VERSION ""

NS_ :

BS_:

BU_: VCU BCM SS IPC ABS ACU
VAL_TABLE_ Rolling_Counter_0x85 15 "Invalid" ;
VAL_TABLE_ ACU_Crash_Sts 3 "Invalid Value" 2 "Invalid Value" 1 "Crash_Detected" 0 "No_Event" ;
VAL_TABLE_ ACU_Airbag_Deployment_Status 3 "Invalid Value" 2 "Invalid Value" 1 "Airbag_Deployment" 0 "No_Airbag_Deployment" ;
VAL_TABLE_ Rolling_Counter_0x381 15 "Invalid" ;
VAL_TABLE_ ACU_Seat_Occupancy_Passenger 3 "Failure" 2 "Not_Available" 1 "Seat Occupied" 0 "Seat_Not_Occupied" ;
VAL_TABLE_ ACU_Seat_Belt_Status_Passenger 3 "Failure" 2 "Not_Available" 1 "Buckled" 0 "Not_buckled" ;
VAL_TABLE_ ACU_Seat_Belt_Status_Driver 3 "Failure" 2 "Not_Available" 1 "Buckled" 0 "Not_buckled" ;
VAL_TABLE_ Alive_ACU_0x488 21 "Invalid" ;
VAL_TABLE_ ACU_Malfunction 0 "ACU_Failure" 1 "ACU_Normal_Operation" ;
VAL_TABLE_ ACU_Pre_Drive_Check 0 "ACU_Pre_Drive_Check" 1 "ACU_Normal_Operation" ;
VAL_TABLE_ ACU_in_Plant_Mode 0 "ACU_in_Plant_Mode" 1 "ACU_in_Normal_Mode" ;
VAL_TABLE_ ACU_PAB_Suppression 0 "Not_Suppressed" 1 "Suppressed" 2 "Function Failure" 3 "Invalid_Value" ;
VAL_TABLE_ ACU_Airbag_Disabled 0 "ACU_AirBag_Disabled" 1 "ACU_Normal_Operation" ;
VAL_TABLE_ ACU_Development_Calibration 0 "ACU_Dev_Calibrated" 1 "ACU_Normal_Operation" ;
VAL_TABLE_ ACU_In_Disposal_Mode 0 "ACU_In_Disposal_Mode" 1 "ACU_Normal_Operation" ;
VAL_TABLE_ ACU_VehicleFailureLevel 0 "Normal" 1 "Slight Fault" 2 "Minor fault" 3 "General fault" 4 "Serious Fault" 5 "Fatal fault" ;
VAL_TABLE_ ACU_Seatbelt_Reminder_Request 0 "Seatbelt reminder NOT activated" 1 "Seatbelt reminder activated" ;
VAL_TABLE_ ACU_SBR_Chime_Req 0 "No Active Chime" 1 "Active Chime" ;
VAL_TABLE_ ACU_SBR_Blinking_Req 0 "No Blinking" 1 "Blinking 1Hz" ;
VAL_TABLE_ ABS_DTCDecReqTorque 4095 " Invalid" ;
VAL_TABLE_ ABS_DTCActiveSts 0 "Not Active" 1 " Active" ;
VAL_TABLE_ ABS_DTCSystemSts 0 "No Fault" 1 "Fault" ;
VAL_TABLE_ ABS_DTCDecReqTorqueV 0 "Invalid" 1 "Valid" ;
VAL_TABLE_ ABS_ASRDecReqTorque 4095 " Invalid" ;
VAL_TABLE_ ABS_ASRSwState 0 "OFF(关闭PTC功能)" 1 "ON(开启PTC功能)" ;
VAL_TABLE_ ABS_ASRActiveSts 0 "Not Active" 1 " Active" ;
VAL_TABLE_ ABS_ASRSystemSts 0 "Normal" 1 "Fault" ;
VAL_TABLE_ ABS_ASRDecReqTorqueV 0 "Invalid" 1 "Valid" ;
VAL_TABLE_ ABS_MasterCylinderPressure 4095 "Invalid" ;
VAL_TABLE_ ALIVE_ABS_0x118 15 "Invalid" ;
VAL_TABLE_ ABS_HazardLightsOnReq 0 "No request" 1 "request" ;
VAL_TABLE_ ABS_BrakeLightsOnReq 0 "No request" 1 "request" ;
VAL_TABLE_ ABS_TcsFlgFlt 1 "Failure" 0 "no Failure" ;
VAL_TABLE_ ABS_TCS_Active 1 "active" 0 "inactive" ;
VAL_TABLE_ ABS_ABSActive 1 "active" 0 "inactive" ;
VAL_TABLE_ ABS_EBDFault 1 "Fault" 0 "Normal" ;
VAL_TABLE_ ABS_ABSFault 1 "Fault" 0 "Normal" ;
VAL_TABLE_ ABS_TCS_OFF_State 1 "open" 0 "close" ;
VAL_TABLE_ ABS_VehicleFailureLevel 0 "Normal" 1 "Slight Fault" 2 "Minor fault" 3 "General fault" 4 "Serious Fault" 5 "Fatal fault" ;
VAL_TABLE_ ABS_RBSInhibitFlag 0 "Not Inhibit" 1 "Inhibit" ;
VAL_TABLE_ ABS_EBDActive 1 "active" 0 "inactive" ;
VAL_TABLE_ ABS_VehicleSpeed 32767 "Invalid" ;
VAL_TABLE_ ABS_VehicleSpeedV 0 "Invalid" 1 "Valid" ;
VAL_TABLE_ ABS_WheelSpeedFL 8191 "Invalid" ;
VAL_TABLE_ ABS_PulseCounterFLV 0 "Invalid" 1 "Valid" ;
VAL_TABLE_ ABS_WheelSpeedFLV 0 "Invalid" 1 "Valid" ;
VAL_TABLE_ ABS_WheelSpeedFR 8191 "Invalid" ;
VAL_TABLE_ ABS_PulseCounterFRV 0 "Invalid" 1 "Valid" ;
VAL_TABLE_ ABS_WheelSpeedFRV 0 "Invalid" 1 "Valid" ;
VAL_TABLE_ ABS_WheelSpeedRL 8191 "Invalid" ;
VAL_TABLE_ ABS_PulseCounterRLV 0 "Invalid" 1 "Valid" ;
VAL_TABLE_ ABS_WheelSpeedRLV 0 "Invalid" 1 "Valid" ;
VAL_TABLE_ ABS_WheelSpeedRR 8191 "Invalid" ;
VAL_TABLE_ ABS_PulseCounterRRV 0 "Invalid" 1 "Valid" ;
VAL_TABLE_ ABS_WheelSpeedRRV 0 "Invalid" 1 "Valid" ;
VAL_TABLE_ VCU_VehicleFailureLevel 0 "Normal" 1 "Slight Fault" 2 "Minor fault" 3 "General fault" 4 "Serious Fault" 5 "Fatal fault" ;
VAL_TABLE_ VCU_EDSCAN_ERR 1 "Error" 0 "Normal" ;
VAL_TABLE_ VCU_BmsCAN_ERR 1 "Error" 0 "Normal" ;
VAL_TABLE_ VCU_DcdcCAN_ERR 1 "Error" 0 "Normal" ;
VAL_TABLE_ VCU_AbsCAN_ERR 1 "Error" 0 "Normal" ;
VAL_TABLE_ VCU_ACUCAN_ERR 1 "Error" 0 "Normal" ;
VAL_TABLE_ VCU_BcmCAN_ERR_reserved 1 "Error" 0 "Normal" ;
VAL_TABLE_ VCU_BrakeSys_Err 1 "Error" 0 "Normal" ;
VAL_TABLE_ VCU_AccPed_ERR 1 "Error" 0 "Normal" ;
VAL_TABLE_ VCU_Shift_ERR 1 "Error" 0 "Normal" ;
VAL_TABLE_ VCU_EPSCAN_ERR 1 "Error" 0 "Normal" ;
VAL_TABLE_ VCU_EvccCAN_ERR 1 "Error" 0 "Normal" ;
VAL_TABLE_ VCU_FlgHVIL_ERR 1 "Error" 0 "Normal" ;
VAL_TABLE_ VCU_ObcCAN_ERR 1 "Error" 0 "Normal" ;
VAL_TABLE_ VCU_SSCAN_ERR 1 "Error" 0 "Normal" ;
VAL_TABLE_ VCU_EacCAN_ERR 1 "Error" 0 "Normal" ;
VAL_TABLE_ VCU_AccPedalOutRange 1 "Error" 0 "Normal" ;
VAL_TABLE_ VCU_CreepDisable_stt 0 "Enable" 1 "disable" ;
VAL_TABLE_ VCU_RDCSts 0 "inactive" 1 "Active" ;
VAL_TABLE_ VCU_RBCSts 0 "inactive" 1 "Active" ;
VAL_TABLE_ VCU_BrkPedalSWSts 0 "Notpressed" 1 "pressed" 2 "notused" 3 "Invalid" ;
VAL_TABLE_ Brakefluid_levelSts 0 "Normal" 1 "Low" 2 "Disconnect" 3 "reserve" ;
VAL_TABLE_ VCU_HandBrakeSts 0 "released" 1 "notreleased" ;
VAL_TABLE_ VCU_RegenLevelfeed 0 "OFF" 1 "ON" ;
VAL_TABLE_ VCU_PowerLimit 0 "NoLimit" 1 "Limit" ;
VAL_TABLE_ VCU_AccPedaPosValid 0 "Valid" 1 "Invalid" ;
VAL_TABLE_ VCU_VehicleHVStatus 0 "NotReady" 1 "HVOn" 2 "Ready" ;
VAL_TABLE_ VCU_VacuumPresWrn 0 "Normal" 1 "Slight Insufficient" 2 "Serious Insufficient" 3 "Invalid" ;
VAL_TABLE_ VCU_VacuumSts 0 "Normal" 1 "slow leak" 2 "quick leak" 3 "Invalid" ;
VAL_TABLE_ VCU_InstantPowerConsump 1023 "Invalid" ;
VAL_TABLE_ VCU_AveragePowerConsump 1023 "Invalid" ;
VAL_TABLE_ VCU_LowSOCWarning 0 "Normal" 1 "Low SOC" ;
VAL_TABLE_ VCU_TqReductionRqstResponse 0 "inactive" 1 "Active" ;
VAL_TABLE_ VCU_DrvModeSts 0 "Normal(正常模式)" 1 "Eco(经济模式)" 2 "Sport(运动模式)" 3 "Reserved(预留)" ;
VAL_TABLE_ VCU_VacuumPumpEna 1 "Enable" 0 "Disable" ;
VAL_TABLE_ ALIVE_VCU_0x155 15 "Invalid" ;
VAL_TABLE_ VCU_VecChrgRqst 0 "Default" 1 "permit" 2 "forbid" ;
VAL_TABLE_ VCU_Vechg_Status 3 "Charging Fault" 2 "Charging Complete" 1 "Charging in process" 0 "Charging not in process" ;
VAL_TABLE_ VCU_VecOptMod 0 "Sleep(休眠)" 1 "Initial(初始化)" 2 "PowerOn(上电)" 3 "Drive(行驶)" 4 "Charging(充电)" 5 "PowerOFF(下电)" 6 "Err(故障)" 7 "LimpHome" 8 "LVCharging(馈电补电)" ;
VAL_TABLE_ VCU_BMSHvPowOnRqst 1 "allow" 0 "forbid" ;
VAL_TABLE_ VCU_VecActGearStsV 1 "Invalid" 0 "Valid" ;
VAL_TABLE_ VCU_VecActGearSts 7 "Fault" 6 "Reserved" 5 "Reserved" 4 "Reserved" 3 "D" 2 "N" 1 "R" 0 "P" ;
VAL_TABLE_ VCU_LV_topupSts 3 "Rserved" 2 "Finish supply" 1 "suppling" 0 "dissupply" ;
VAL_TABLE_ VCU_DrTorqRqstV 1 "Invalid" 0 "Valid" ;
VAL_TABLE_ VCU_ABS_TrqReqOrLmt 65535 "Invalid" ;
VAL_TABLE_ VCU_RemainMileageVD 0 "Valid" 1 "Invalid" ;
VAL_TABLE_ ALIVE_VCU_0x123 15 "Invalid" ;
VAL_TABLE_ VCU_Drive_TargetTqMin 1023 "Invalid" ;
VAL_TABLE_ VCU_Drive_TargetTqMax 1023 "Invalid" ;
VAL_TABLE_ Rolling_Counter_0x20D 15 "Invalid" ;
VAL_TABLE_ VCU_ODO 1048575 "Invalid" ;
VAL_TABLE_ Rolling_Counter_0x432 15 "Invalid" ;
VAL_TABLE_ IPC_FOTA_State 0 "INIT" 1 "NORMAL" 2 "FOTA FLASHING" 3 "Reserved" 4 "FAIL-SAFE-ERROR" 5 "Reserved" 6 "REMOTE DIAGNOSTICS" 7 "Invalid" ;
VAL_TABLE_ VCU_FOTA_StateConfirm 0 "INIT" 1 "NORMAL" 2 "FOTA FLASHING" 3 "Reserved" 4 "FAIL-SAFE-ERROR" 5 "Reserved" 6 "REMOTE DIAGNOSTICS" 7 "Invalid" ;
VAL_TABLE_ IPC_Wiper_Repair_Mode 0 "Off" 1 "On" 2 "no action" 3 "Invalid" ;
VAL_TABLE_ IPC_St_Dimming 15 "Invalid" 14 "Level 15" 13 "Level 14" 12 "Level 13" 11 "Level 12" 10 "Level 11" 9 "Level 10" 8 "Level 9" 7 "Level 8" 6 "Level 7" 5 "Level 6" 4 "Level 5" 3 "Level 4" 2 "Level 3" 1 "Level 2" 0 "Level 1" ;
VAL_TABLE_ IPC_TripA 65535 "Invalid" ;
VAL_TABLE_ IPC_AverageConsumptionTripA 1023 "Invalid" ;
VAL_TABLE_ IPC_AverageSpeedTripA 4095 "Invalid" ;
VAL_TABLE_ IPC_VehicleFailureLevel 0 "Normal" 1 "Slight Fault" 2 "Minor fault" 3 "General fault" 4 "Serious Fault" 5 "Fatal fault" ;
VAL_TABLE_ IPC_VehSpd 32767 "Invalid" ;
VAL_TABLE_ IPC_Year 255 "Invalid" ;
VAL_TABLE_ IPC_Month 15 "Invalid" ;
VAL_TABLE_ IPC_SelFCheckStatus 1 "selF-check Finish" 0 "selF-checking" ;
VAL_TABLE_ IPC_Day 31 "Invalid" ;
VAL_TABLE_ IPC_Hour 31 "Invalid" ;
VAL_TABLE_ IPC_Min 63 "Invalid" ;
VAL_TABLE_ IPC_Sec 63 "Invalid" ;
VAL_TABLE_ IPC_ODO 1048575 "Invalid" ;
VAL_TABLE_ IPC_ChargeScheduleSet 0 "Disable" 1 "Enabled" 2 "No Action" 3 "Reserved" ;
VAL_TABLE_ IPC_ChargingRequest 0 "No Effect" 1 "Request scheduled start charging" 2 "Request stop" 3 "Reserved" ;
VAL_TABLE_ IPC_EnergyRecSet 0 "OFF(关闭)" 1 "ON(开启)" 2 "Reserved(预留)" 3 "Reserved(预留)" ;
VAL_TABLE_ IPC_HSA_Set 0 "OFF" 1 "ON" 2 "Reserved" 3 "Invalid" ;
VAL_TABLE_ IPC_DriveModeSet 0 "NoReq" 1 "NormalMode" 2 "ECOmode" 3 "SportMode(预留)" ;
VAL_TABLE_ IPC_VCU_CreepDisable_Stt 0 "No request" 1 "request" ;
VAL_TABLE_ IPC_DriveLockSpeedCtl 0 "OFF" 1 "5KMH" 2 "10KMH" 3 "15KMH" 4 "20KMH" 5 "25KMH" 6 "Signal invalid" ;
VAL_TABLE_ MFS_RightControl 0 "Button not Pressed" 1 "Short Press" 2 "Long Press" 3 "Signal invalid" ;
VAL_TABLE_ MFS_LeftControl 0 "Button not Pressed" 1 "Short Press" 2 "Long Press" 3 "Signal invalid" ;
VAL_TABLE_ MFS_DownControl 0 "Button not Pressed" 1 "Short Press" 2 "Long Press" 3 "Signal invalid" ;
VAL_TABLE_ MFS_UpControl 0 "Button not Pressed" 1 "Short Press" 2 "Long Press" 3 "Signal invalid" ;
VAL_TABLE_ MFS_Failure 0 "No Error" 1 "Error" ;
VAL_TABLE_ MFS_VOL_D 3 "Signal invalid" 2 "Long Press" 1 "Short Press" 0 "Unpress" ;
VAL_TABLE_ MFS_VOL_U 3 "Signal invalid" 2 "Long Press" 1 "Short Press" 0 "Unpress" ;
VAL_TABLE_ MFS_OK_Control 0 "Button not Pressed" 1 "Short Press" 2 "Long Press" 3 "Signal invalid" ;
VAL_TABLE_ Rolling_Counter_0x108 15 "Invalid" ;
VAL_TABLE_ SS_DriveModeReq_reserved 1 "press" 0 "no press" ;
VAL_TABLE_ SS_TargetGearReq 7 "Reserved" 4 "Invalid" 3 "D" 2 "N" 1 "R" 0 "Stop Charging" ;
VAL_TABLE_ SS_Fault 6 "Received Date from BCM is invalid" 5 "Received Date from VCU is invalid" 4 "Supply voltage failure" 3 "Position sensor failure" 2 "CAN communication fail" 1 "Shifter failure" 0 "normal" ;
VAL_TABLE_ FR_Wipercontrol_switch 7 "Invalid " 6 "reserved " 5 "reserved " 4 "High " 3 "Int2 " 2 "Int1 " 1 "Low " 0 "OFF" ;
VAL_TABLE_ Front_Wash 3 "Invalid " 2 "Wash " 1 "Mist" 0 "OFF" ;
VAL_TABLE_ SS_FogLight_reserved 0 "OFF" 1 "ON" ;
VAL_TABLE_ RR_Wiper 3 "Invalid " 2 "Wash " 1 "Wipe " 0 "OFF" ;
VAL_TABLE_ SS_lane_change_lampSts 0 "OFF" 1 "Left lane change" 2 "Right lane change" 3 "Reserved" ;
VAL_TABLE_ SS_Overtaking_lamp 0 "OFF" 1 "ON" ;
VAL_TABLE_ SS_TurnIndicatorSts 0 "OFF" 1 "Left On" 2 "Right On" 3 "Reserved" ;
VAL_TABLE_ SS_PosLmpSts 0 "OFF " 1 "ON" ;
VAL_TABLE_ SS_LowBeamSts 0 "OFF" 1 "ON" ;
VAL_TABLE_ SS_HighBeamSts 0 "OFF" 1 "ON" ;
VAL_TABLE_ BCM_FrontLeftDoorAjarStatus 0 "Closed" 1 "Opened" 2 "Reserved" 3 "Signal invalid" ;
VAL_TABLE_ BCM_FrontRightDoorAjarStatus 0 "Closed" 1 "Opened" 2 "Reserved" 3 "Signal invalid" ;
VAL_TABLE_ BCM_RightDoorLockStatusDrv 0 "Unlcoked" 1 "Locked" 2 "Reserved" 3 "Signal invalid" ;
VAL_TABLE_ BCM_LeftDoorLockStatusDrv 0 "Unlcoked" 1 "Locked" 2 "Reserved" 3 "Signal invalid" ;
VAL_TABLE_ BCM_ATWS_St 0 "Secured" 1 "Unsecured" 2 "Alarm" 3 "Partly secured" 4 "Security Failure" 5 "Reserved" 6 "Reserved" 7 "Signal invalid" ;
VAL_TABLE_ BCM_STAT_DoorSpeedLock 0 "OFF" 1 "5KMH" 2 "10KMH" 3 "15KMH" 4 "20KMH" 5 "25KMH" 6 "Signal invalid" ;
VAL_TABLE_ BCM_TurnIndicatorSts 0 "OFF" 1 "LeftOn" 2 "RightOn" 3 "Hazard warning light" ;
VAL_TABLE_ BCM_PosLmpSts 0 "OFF" 1 "ON" 2 "Fault(Reserved)" 3 "SignalInvalid" ;
VAL_TABLE_ BCM_LowBeamSts 0 "OFF" 1 "ON" 2 "Fault(Reserved)" 3 "SignalInvalid" ;
VAL_TABLE_ BCM_HighBeamSts 0 "OFF" 1 "ON" 2 "Fault(Reserved)" 3 "SignalInvalid" ;
VAL_TABLE_ BCM_BrakeLightSts 0 "OFF" 1 "ON" 2 "Fault(Reserved)" 3 "SignalInvalid" ;
VAL_TABLE_ BCM_ReverseLightSts 0 "OFF" 1 "ON" 2 "Fault(Reserved)" 3 "SignalInvalid" ;
VAL_TABLE_ BCM_STAT_LightActivation 0 "OFF" 1 "PositionLight" 2 "LowBeam" 3 "AutoLight" 4 "Reserved" 5 "Reserved" 6 "Reserved" 7 "Signalinvalid" ;
VAL_TABLE_ BCM_Fr_domelampSts 0 "OFF" 1 "ON" 2 "Fault(Reserved)" 3 "SignalInvalid" ;
VAL_TABLE_ BCM_LicensePlateLightSts 0 "OFF" 1 "ON" 2 "Fault(Reserved)" 3 "SignalInvalid" ;
VAL_TABLE_ BCM_STAT_InteriorLight 0 "OFF" 1 "ON" 2 "Fault(Reserved)" 3 "SignalInvalid" ;
VAL_TABLE_ BCM_LV_topupReq 0 "inactive" 1 "Active" 2 "Rserved" 3 "Rserved" ;
VAL_TABLE_ BCM_BatteryVoltage 597 "Invalid" ;
VAL_TABLE_ BCM_Key_CheckSts 0 "Passed" 1 "Invalid" ;
VAL_TABLE_ BCM_Press_BrkPedal_Alert 0 "inactive" 1 "Active" ;
VAL_TABLE_ BCM_EmergencyStop 0 "Normal" 1 "EmergencyStop" 2 "Rserved" 3 "Invalid" ;
VAL_TABLE_ BCM_IGN1RelayOutputSts 0 "inactive" 1 "Active" 2 "Reserved" 3 "Reserved" ;
VAL_TABLE_ BCM_ACCRelayOutputSts 0 "inactive" 1 "Active" 2 "Reserved" 3 "Reserved" ;
VAL_TABLE_ BCM_FLWIN_Postion_Reserved 0 "NotActive" 1 "Closed(Top)" 2 "Open(Bottom)" 3 "80%-Close(Reserved)" 4 "Open-80%(Reserved)" 5 "opening" 6 "closing" 7 "Reserved" ;
VAL_TABLE_ BCM_KEY_MatchSts 0 "No Match" 1 "Match Success" 2 "Match Failed" 3 "Matching" ;
VAL_TABLE_ BCM_FRWIN_Postion_Reserved 0 "NotActive" 1 "Closed(Top)" 2 "Open(Bottom)" 3 "80%-Close(Reserved)" 4 "Open-80%(Reserved)" 5 "opening" 6 "closing" 7 "Reserved" ;
VAL_TABLE_ BCM_PowerMode 0 "OFF" 1 "ACC" 2 "ON" 3 "START" ;
VAL_TABLE_ BCM_BrakeSwSts 0 "Notpressed" 1 "pressed" 2 "notused" 3 "Invalid" ;
VAL_TABLE_ BCM_VehicleFailureLevel 0 "Normal" 1 "Slight Fault" 2 "Minor fault" 3 "General fault" 4 "Serious Fault" 5 "Fatal fault" ;
VAL_TABLE_ BCM_Anti_theftAlarmSetSts 0 "Light" 1 "Horn" 2 "Both" 3 "Invalid" ;
VAL_TABLE_ BCM_FMH_SetSts 0 "OFF" 1 "30s" 2 "60s" 3 "90s" ;
VAL_TABLE_ BCM_IGN1RelayFaultSts 0 "No Fault" 1 "Fault" 2 "Reserved" 3 "Signal Invalid" ;
VAL_TABLE_ BCM_ACCRelayFaultSts 0 "No Fault" 1 "Fault" 2 "Reserved" 3 "Signal Invalid" ;
VAL_TABLE_ EDS_VCU_CtrMode 0 "Inactive" 1 "Toque control mode" 2 "Anti-slide slope" 3 "reserved" ;
VAL_TABLE_ EDS_MotorSpdVD 0 "Valid" 1 "Invalid" ;
VAL_TABLE_ EDS_MotorTqVD 0 "Valid" 1 "Invalid" ;
VAL_TABLE_ EDS_MotorTq 65534 "Abnormal" 65535 "Invaild" ;
VAL_TABLE_ EDS_MotorSpd 65534 "Abnormal" 65535 "Invaild" ;
VAL_TABLE_ EDS_HSA_Sts 0 "Inactive" 1 "Active" 2 "Reserved" 3 "Invalid" ;
VAL_TABLE_ EDS_DriveSTS 0 "Regeneration control" 1 "Drive control" 2 "Zero control" ;
VAL_TABLE_ EDS_StsMode 0 "DeFault(默认值)" 1 "Init(初始化)" 2 "Standby(待机)" 3 "Precharge(预充)" 4 "Normal(正常运行)" 5 "HVReady(高压上电完成)" 11 "ShutDown(关闭)" 12 "AFterRun(运行后)" 13 "Failure" 14 "PowerOFF(下电)" ;
VAL_TABLE_ EDS_VehicleFailureLevel 0 "Normal" 1 "Slight Fault" 2 "Minor fault" 3 "General fault" 4 "Serious Fault" 5 "Fatal fault" ;
VAL_TABLE_ EDS_HSA_Fault 0 "Normal" 1 "Level 1" 2 "Level 2" 3 "Invalid" ;
VAL_TABLE_ ALIVE_EDS_0x367 15 "Invalid" ;
VAL_TABLE_ EDS_MotTempSenFault 0 "Normal" 1 "Error" ;
VAL_TABLE_ EDS_EDSOverTempAlarm 0 "Normal" 1 "Error" ;
VAL_TABLE_ EDS_EDSOverTempFault 0 "Normal" 1 "Error" ;
VAL_TABLE_ EDS_LV_VotagtFault 0 "Normal" 1 "Error" ;
VAL_TABLE_ EDS_PhashOverCurrentSWFault 0 "Normal" 1 "Error" ;
VAL_TABLE_ EDS_EDSCurrentSenVFault 0 "Normal" 1 "Error" ;
VAL_TABLE_ EDS_EDSCurrentSenWFault 0 "Normal" 1 "Error" ;
VAL_TABLE_ EDS_EDSHVOverVoltageAlarm 0 "Normal" 1 "Error" ;
VAL_TABLE_ EDS_EDSHVOverVoltageFault 0 "Normal" 1 "Error" ;
VAL_TABLE_ EDS_EDSHVUnderVoltageAlarm 0 "Normal" 1 "Error" ;
VAL_TABLE_ EDS_EDSHVUnderVoltageFault 0 "Normal" 1 "Error" ;
VAL_TABLE_ EDS_MotOverTempAlarm 0 "Normal" 1 "Error" ;
VAL_TABLE_ EDS_MotOverTempFault 0 "Normal" 1 "Error" ;
VAL_TABLE_ EDS_EDSDisChgFault 0 "Normal" 1 "Error" ;
VAL_TABLE_ EDS_EDSHVSenFault 0 "Normal" 1 "Error" ;
VAL_TABLE_ EDS_12VOverVoltageAlarm 0 "Normal" 1 "Error" ;
VAL_TABLE_ EDS_12VUnderVoltageAlarm 0 "Normal" 1 "Error" ;
VAL_TABLE_ EDS_MotOverAlarm 0 "Normal" 1 "Error" ;
VAL_TABLE_ EDS_MotOverFault 0 "Normal" 1 "Error" ;
VAL_TABLE_ EDS_PhashOverCurrentHWFault 0 "Normal" 1 "Error" ;
VAL_TABLE_ EDS_EDSCurrentSenUFault 0 "Normal" 1 "Error" ;
VAL_TABLE_ EDS_VCULostFault 0 "Normal" 1 "Error" ;
VAL_TABLE_ EDS_BMSLostFault 0 "Normal" 1 "Error" ;
VAL_TABLE_ EDS_MotRotSenFault 0 "Normal" 1 "Error" ;
VAL_TABLE_ EDS_MotBlockedFault 0 "Normal" 1 "Error" ;
VAL_TABLE_ EDS_EDSChksumFault 0 "Normal" 1 "Error" ;
VAL_TABLE_ EDS_MotTrqLimtFault 0 "Normal" 1 "Error" ;
VAL_TABLE_ EDS_VCUChksumFault 0 "Normal" 1 "Error" ;
VAL_TABLE_ EDS_EDSEnableFault 0 "Normal" 1 "Error" ;
VAL_TABLE_ EDS_IGBTFault 0 "Normal" 1 "Error" ;
VAL_TABLE_ EDS_CANBUSOFFFault 0 "Normal" 1 "Error" ;
VAL_TABLE_ EDS_EDSTempSensorErr 0 "Normal" 1 "Error" ;
VAL_TABLE_ EDS_HWCapOverVolt 0 "Normal" 1 "Error" ;
VAL_TABLE_ EDS_SWCapOverVolt 0 "Normal" 1 "Error" ;
VAL_TABLE_ EDS_EDSMemoryFlt 0 "Normal" 1 "Error" ;
VAL_TABLE_ EDS_InitMode 0 "Normal" 1 "Error" ;
VAL_TABLE_ Rolling_counter_0x17E 15 "Invalid" ;
VAL_TABLE_ EPS_S_WarningLampYellow 0 "OFF" 1 "ON" ;
VAL_TABLE_ EPS_S_SaFeLampRed 0 "OFF" 1 "ON" ;
VAL_TABLE_ EPS_SteerWheelAngle 65535 "Invalid" ;
VAL_TABLE_ EPS_SteerWhlRotSpd 16383 "Invalid" ;
VAL_TABLE_ EPS_SteerWheelRotSpdStatus 0 "Valid" 1 "Invalid" ;
VAL_TABLE_ EPS_SteeringAngleValid 0 "Valid" 1 "Invalid" ;
VAL_TABLE_ EPS_VehicleFailureLevel 0 "Normal" 1 "Slight Fault" 2 "Minor fault" 3 "General fault" 4 "Serious Fault" 5 "Fatal fault" ;
VAL_TABLE_ EPS_status 0 "NoFailure" 1 "SlightFailure" 2 "CriticalFailure" 3 "FatalFailure" ;
VAL_TABLE_ EPS_Calibrated 0 "NotCalibrated" 1 "Calibrated" ;
VAL_TABLE_ EPS_Systemstatus 0 "NoFailure" 1 "SlightFailure" 2 "CriticalFailure" 3 "FatalFailure" ;
VAL_TABLE_ Alive_SAS_0x17F 15 "Invalid" ;
VAL_TABLE_ EPS_SteeringTorque 4095 "Invalid" ;
VAL_TABLE_ EPS_SASFailure 0 "Failure" 1 "No failure" ;
VAL_TABLE_ EPS_SASStsSnsr 1 "sensor value valid" 0 "sensor value Invalid" ;
VAL_TABLE_ EPS_TorqSensorStatus 0 "Valid" 1 "Invalid" ;
VAL_TABLE_ EPS_Mode 3 " Invalid" 1 "low assist" 0 "Full assist" ;
VAL_TABLE_ EPS_EpsFailed 1 "Failed" 0 "not Failed" ;
VAL_TABLE_ Rolling_Counter_0x2A1 15 "Invalid" ;
VAL_TABLE_ EVCC_ChargeGunSts 1 "Plug In" 0 "no Plug in" ;
VAL_TABLE_ EVCC_VehicleFailureLevel 0 "Normal" 1 "Slight Fault" 2 "Minor fault" 3 "General fault" 4 "Serious Fault" 5 "Fatal fault" ;
VAL_TABLE_ EVCC_ChargeMode 2 "DC Mode " 1 "AC Mode " 0 "Default" ;
VAL_TABLE_ EVCC_CP_Sts 12 "F~" 11 "E~" 10 "D~" 9 "C~" 8 "B~" 7 "A~" 6 "F" 5 "E" 4 "D" 3 "C" 2 "B" 1 "A" 0 "No CP" ;
VAL_TABLE_ EVCC_PP_Value 7 "CC GND" 6 "1500" 5 "680" 4 "220" 3 "100" 2 "Connection" 1 "Half Connection " 0 "No Connection" ;
VAL_TABLE_ EVCC_Lock_Sts 4 "Error" 3 "Unlocking" 2 "Locked" 1 "Locking " 0 "Unlock" ;
VAL_TABLE_ EVCC_DCFCPortsTempErr 1 "Error" 0 "Normal" ;
VAL_TABLE_ Rolling_Counter_0x3E0 15 "Invalid" ;
VAL_TABLE_ EVCC_IPC_Ack_ChgSche_stt 0 "Disabled" 1 "Enabled" 2 "Reserved" 3 "Invalid" ;
VAL_TABLE_ Rolling_Counter_0x219 15 "Invalid" ;
VAL_TABLE_ EVCC_ChargeAllow 1 "Allow " 0 "Not allow" ;
VAL_TABLE_ Rolling_Counter_0x125 15 "Invalid" ;
VAL_TABLE_ Rolling_Counter_0x216 15 "Invalid" ;
VAL_TABLE_ BMS_RemainChargeTime 16383 "Invalid" ;
VAL_TABLE_ BMS_ChgVoltage_REQ 16383 "Invalid" ;
VAL_TABLE_ BMS_ChgCurrent_REQ 65535 "Invalid" ;
VAL_TABLE_ Rolling_Counter_0x215 15 "Invalid" ;
VAL_TABLE_ BMS_SOE 255 "Invalid" ;
VAL_TABLE_ BMS_HWCrash_Sts 1 "Crash " 0 "No Crash" ;
VAL_TABLE_ BMS_HVIL_STS 2 "out of range" 1 "Open" 0 "Closed" ;
VAL_TABLE_ BMS_IGN_Sts 1 "ON " 0 "OFF" ;
VAL_TABLE_ BMS_Sys_STS 8 "Invalid" 7 "Failure, unable to operate" 6 "BCU Sleep mode" 5 "Successful Power Down" 4 "Power Down process" 3 "Successful Power Down of HV" 2 "Successful High Voltage Power Up" 1 "Self-check passes, can be high-voltage" 0 "Initialization of power on, self-checking" ;
VAL_TABLE_ BMS_HVOnOff_STS 3 "Fail to HV on " 2 "HV On " 1 "Precharge " 0 "HV Off" ;
VAL_TABLE_ BMS_Balance_STS 1 "active " 0 "Inactive" ;
VAL_TABLE_ BMS_BatBalance_ERR 1 "normal " 0 "Error" ;
VAL_TABLE_ BMS_ISU_Status 3 "Level3(<100 Ohms/V)" 2 "Level2(<200 Ohms/V)" 1 "Level1 <500 Ohms/V ~ >200 Ohms/V" 0 "Normal (> 500 Ohms/V)" ;
VAL_TABLE_ BMS_ERR_LEV 7 "Battery locked -Reserved" 6 "Fault, needs Shutdown and Wakeup" 5 "Emergency off condition" 4 "Delayed power down with FTTI" 3 "Power down without FTTI" 2 "Limp Home" 1 " Warning (any warning in system)" 0 "No error" ;
VAL_TABLE_ BMS_Vehicle_ERR_LEV 0 "Normal" 1 "Slight Fault" 2 "Minor fault" 3 "General fault" 4 "Serious Fault" 5 "Fatal fault" ;
VAL_TABLE_ BMS_HV_Sts 4 "AC Charging" 3 "DC Charging" 2 "HV ON" 1 "Precharge" 0 "HV Off" ;
VAL_TABLE_ BMS_Warning_Flag_Reserved_08 1 "Warning" 0 "No warning" ;
VAL_TABLE_ BMS_Warning_Flag_Reserved_07 1 "Warning" 0 "No warning" ;
VAL_TABLE_ BMS_Warning_Flag_Reserved_11 1 "Warning" 0 "No warning" ;
VAL_TABLE_ BMS_Warning_Flag_Reserved_10 1 "Warning" 0 "No warning" ;
VAL_TABLE_ BMS_Warning_Flag_Reserved_09 1 "Warning" 0 "No warning" ;
VAL_TABLE_ BMS_Warning_Flag_Reserved_13 1 "Warning" 0 "No warning" ;
VAL_TABLE_ BMS_Warning_Flag_Reserved_12 1 "Warning" 0 "No warning" ;
VAL_TABLE_ BMS_Warning_Flag_Reserved_06 1 "Warning" 0 "No warning" ;
VAL_TABLE_ BMS_Warning_Flag_Reserved_05 1 "Warning" 0 "No warning" ;
VAL_TABLE_ BMS_Warning_Flag_Reserved_04 1 "Warning" 0 "No warning" ;
VAL_TABLE_ BMS_MalfunctionSts 1 "Malfunction indicator lamp ON" 0 "Malfunction indicator lamp OFF" ;
VAL_TABLE_ BMS_LowBattery 2 "Extremely low level" 1 "Low level" 0 "No warning" ;
VAL_TABLE_ BMS_BatteryReplacement 1 "Warning" 0 "No warning" ;
VAL_TABLE_ BMS_PackTempSts 2 "Under Temperature Warning" 1 "Over Temperature Warning" 0 "No warning" ;
VAL_TABLE_ BMS_ThermalRunaway 1 "Warning" 0 "No warning" ;
VAL_TABLE_ Rolling_Counter_0x493 15 "Invalid" ;
VAL_TABLE_ Rolling_Counter_0x174 15 "Invalid" ;
VAL_TABLE_ BMS_PackCur_MEAS 65535 "Invalid" ;
VAL_TABLE_ BMS_AllowDischgCurr 65535 "Invalid" ;
VAL_TABLE_ BMS_AllowDischgCurrPeak 65535 "Invalid" ;
VAL_TABLE_ Rolling_Counter_0x176 15 "Invalid" ;
VAL_TABLE_ BMS_HVLinkVol_MEAS 65535 "Invalid" ;
VAL_TABLE_ BMS_HVPackVol_MEAS 65535 "Invalid" ;
VAL_TABLE_ Rolling_Counter_0x20B 15 "Invalid" ;
VAL_TABLE_ POD_DCDC_Max_Current_Out 1023 "Invalid" ;
VAL_TABLE_ DCDC_Temp_mosfet 255 "Invalid" ;
VAL_TABLE_ DCDC_Voltage_Output 1023 "Invalid" ;
VAL_TABLE_ DCDC_Current_Output 255 "Invalid" ;
VAL_TABLE_ DCDC_Output_STS 0 "DCDC_OFF" 1 "DCDC_STANDBY" 2 "DCDC_ON" 3 "DCDC_RESERVED" 4 "DCDC_DEGRAEDED" 5 "DCDC_FAULT_SHUTDOWN" 6 "DCDC_EMEGENCY_SHUTDOWN" 7 "DCDC_SNA" ;
VAL_TABLE_ DCDC_Temp_heatsink 255 "Invalid" ;
VAL_TABLE_ Rolling_Counter_0x406 15 "Invalid" ;
VAL_TABLE_ DCDC_FaultLevel 5 "Level5,Fatal fault" 4 "Level4,Serious fault" 3 "Level3,General fault" 2 "Level2,Minor fault" 1 "Level1,slight fault" 0 "No Fault" ;
VAL_TABLE_ DCFC_FaultLevel 0 "No Fault" 2 "Level2: Serous Fault " 3 "Level3: Fatal Fault" ;
VAL_TABLE_ Rolling_Counter_0x20A 15 "Invalid" ;
VAL_TABLE_ DCFC_Voltage_Input 1023 "Invalid" ;
VAL_TABLE_ DCDC_PTC_Temp 255 "Invalid" ;
VAL_TABLE_ DCFC_Neg_Temp_BusBar 255 "Invalid" ;
VAL_TABLE_ DCFC_STATE 0 "DCFC_Contactors_Open_e" 1 "DCFC_Contactors_Closing" 2 "DCFC_Contactors_Close" 3 "DCFC_Contactors_Opening" 4 "DCFC_Contactors_Weld" 7 "DCFC_SNA" ;
VAL_TABLE_ DCFC_PTC_Status 3 "invalid" 2 "reserved" 1 "ON" 0 "OFF" ;
VAL_TABLE_ Rolling_Counter_0x209 15 "Invalid" ;
VAL_TABLE_ BMS_MaxDischgPwr_ALW 4095 "Invalid" ;
VAL_TABLE_ BMS_MaxChgPwr_ALW 4095 "Invalid" ;
VAL_TABLE_ BMS_MaxDischgPwr_Peak 4095 "Invalid" ;
VAL_TABLE_ BMS_MaxChgPwr_Peak 4095 "Invalid" ;
VAL_TABLE_ Rolling_Counter_0x332 15 "Invalid" ;
VAL_TABLE_ BMS_PackTemp_Infor 255 "Invalid" ;
VAL_TABLE_ Rolling_Counter_0x330 15 "Invalid" ;
VAL_TABLE_ BMS_ContactorAging 2 "Fault: counter reach 98%" 1 "Warning: counter reach 90%" 0 "Normal" ;
VAL_TABLE_ Rolling_Counter_0x177 15 "Invalid" ;
VAL_TABLE_ BMS_HVBusVol_MEAS 65535 "Invalid" ;
VAL_TABLE_ BMS_HVFuseVol_MEAS 65535 "Invalid" ;
VAL_TABLE_ Rolling_Counter_0x214 15 "Invalid" ;
VAL_TABLE_ BMS_Display_SOC 1023 "Invalid" ;
VAL_TABLE_ Rolling_Counter_0x375 15 "Invalid" ;
VAL_TABLE_ BMS_MainPosRelay_ERR 1 "normal " 0 "Error" ;
VAL_TABLE_ BMS_MainPosRelay_STS 4 "stuck open" 3 "stuck closed" 2 "closed" 1 "open" 0 "reserved" ;
VAL_TABLE_ BMS_PreChgRelay_ERR 1 "normal " 0 "error" ;
VAL_TABLE_ BMS_PreChgRelay_STS 4 "stuck open" 3 "stuck closed" 2 "closed" 1 "open" 0 "reserved" ;
VAL_TABLE_ BMS_TotalNegRelay_STS 4 "stuck open" 3 "stuck closed" 2 "closed" 1 "open" 0 "reserved" ;
VAL_TABLE_ BMS_TotalNegRelay_ERR 1 "normal " 0 "Error" ;
VAL_TABLE_ Rolling_Counter_0x305 15 "Invalid" ;
VAL_TABLE_ BMS_VCU_Insulation_Mon_Sts 1 "OFF" 0 "ON" ;
VAL_TABLE_ Rolling_Counter_0x455 15 "Invalid" ;
VAL_TABLE_ BMS_PackInsu_ERR 2 "Lv2-Short to vbat and open line" 1 "Lv1 - Short to ground" 0 "Lv0-No Err" ;
VAL_TABLE_ BMS_CellVoltDiff_ERR 3 "Level3 Reserve" 2 "Level2 Serious alarm value" 1 "Level1 General alarm value" 0 "Level0 Normal" ;
VAL_TABLE_ BMS_PackOverCurr_ERR 2 "Serious Alarm value" 1 "General Alarm Value" 0 "Normal" ;
VAL_TABLE_ BMS_HVIL_Err 3 "Level3" 2 "Level2" 1 "Level1" 0 "Normal" ;
VAL_TABLE_ BMS_CellHighVol_ERR 3 "Level3 Reserve" 2 "Level2 Serious alarm value" 1 "Level1 General alarm value" 0 "Level0 Normal" ;
VAL_TABLE_ BMS_CellLowVol_ERR 3 "Level3 Reserve" 2 "Level2 Serious alarm value" 1 "Level1 General alarm value" 0 "Level0 Normal" ;
VAL_TABLE_ BMS_PackLowVol_ERR 3 "Level3 Reserve" 2 "Level2 Serious alarm value" 1 "Level1 General alarm value" 0 "Level0 Normal" ;
VAL_TABLE_ BMS_PackHighVol_ERR 3 "Level3 Reserve" 2 "Level2 Serious alarm value" 1 "Level1 General alarm value" 0 "Level0 Normal" ;
VAL_TABLE_ BMS_ProbeHighTemp_ERR 3 "Level3 Reserve" 2 "Level2 Serious alarm value" 1 "Level1 General alarm value" 0 "Level0 Normal" ;
VAL_TABLE_ BMS_ProbeTempDiff_ERR 3 "Level3 Reserve" 2 "Level2 Serious alarm value" 1 "Level1 General alarm value" 0 "Level0 Normal" ;
VAL_TABLE_ BMS_FuseStatus_ERR 1 "Fuse blow" 0 "Normal" ;
VAL_TABLE_ BMS_ProbeLowTemp_ERR 3 "Level3 Reserve" 2 "Level2 Serious alarm value" 1 "Level1 General alarm value" 0 "Level0 Normal" ;
VAL_TABLE_ Rolling_Counter_0x286 15 "Invalid" ;
VAL_TABLE_ DCFC_OUT_DC_V 65535 "Invalid" ;
VAL_TABLE_ DCFC_OUT_DC_I 16383 "Invalid" ;
VAL_TABLE_ DCFC_DCCharge_line_V 65535 "Invalid" ;
VAL_TABLE_ DCDC_evt_BUS_OFF 1 "Error" 0 "Normal" ;
VAL_TABLE_ DCDC_evt_MIA 1 "Error" 0 "Normal" ;
VAL_TABLE_ DCDC_evt_E2E 1 "Error" 0 "Normal" ;
VAL_TABLE_ DCDC_evt_Calibration_Flt 1 "Error" 0 "Normal" ;
VAL_TABLE_ DCDC_evt_flash_Failure 1 "Error" 0 "Normal" ;
VAL_TABLE_ DCDC_evt_FaultLatchCircuit 1 "Error" 0 "Normal" ;
VAL_TABLE_ DCDC_evt_HV_VoltSensFlt 1 "Error" 0 "Normal" ;
VAL_TABLE_ DCDC_evt_HV_OverVoltFlt 1 "Error" 0 "Normal" ;
VAL_TABLE_ DCDC_evt_HV_UnderVoltFlt 1 "Error" 0 "Normal" ;
VAL_TABLE_ DCDC_evt_LV_VoltSensFlt 1 "Error" 0 "Normal" ;
VAL_TABLE_ DCDC_evt_LVBatt_OverVoltFlt 1 "Error" 0 "Normal" ;
VAL_TABLE_ DCDC_evt_LVBatt_UnderVoltFlt 1 "Error" 0 "Normal" ;
VAL_TABLE_ DCDC_evt_LVBatt_SensorFlt 1 "Error" 0 "Normal" ;
VAL_TABLE_ DCDC_evt_LV_RedundancyFlt 1 "Error" 0 "Normal" ;
VAL_TABLE_ DCDC_evt_LV_CurrSensFlt 1 "Error" 0 "Normal" ;
VAL_TABLE_ DCDC_evt_LV_OverCurr 1 "Error" 0 "Normal" ;
VAL_TABLE_ DCDC_evt_ReverseCurrFlt 1 "Error" 0 "Normal" ;
VAL_TABLE_ DCDC_evt_Heater_TempSensorFlt 1 "Error" 0 "Normal" ;
VAL_TABLE_ DCDC_evt_Mosfet_TempSensorFlt 1 "Error" 0 "Normal" ;
VAL_TABLE_ DCDC_evt_Mosfet_OverTemp 1 "Error" 0 "Normal" ;
VAL_TABLE_ DCDC_evt_HeatSink_TempSensorFlt 1 "Error" 0 "Normal" ;
VAL_TABLE_ DCDC_evt_HeatSink_OverTemp 1 "Error" 0 "Normal" ;
VAL_TABLE_ DCDC_evt_Heater_OverTempFlt 1 "Error" 0 "Normal" ;
VAL_TABLE_ DCDC_evt_Heater_ShortIGBTFlt 1 "Error" 0 "Normal" ;
VAL_TABLE_ DCDC_evt_LV_ShortOutputFlt 1 "Error" 0 "Normal" ;
VAL_TABLE_ DCDC_evt_sw_BMS_CrashFlt 1 "Error" 0 "Normal" ;
VAL_TABLE_ DCDC_evt_BMS_HVILFlt 1 "Error" 0 "Normal" ;
VAL_TABLE_ DCFC_evt_BusbarSensFlt 1 "Error" 0 "Normal" ;
VAL_TABLE_ DCFC_evt_Contactor_Welded 1 "Error" 0 "Normal" ;
VAL_TABLE_ DCFC_evt_ContactorStuckOpen 1 "Error" 0 "Normal" ;
VAL_TABLE_ DCFC_evt_CP_UnderVoltFlt 1 "Error" 0 "Normal" ;
VAL_TABLE_ DCFC_evt_DataInvalidVCUFlt 1 "Error" 0 "Normal" ;
VAL_TABLE_ DCFC_evt_ChargePortSensFlt 1 "Error" 0 "Normal" ;
VAL_TABLE_ DCFC_evt_OverChargePortFlt 1 "Error" 0 "Normal" ;
VAL_TABLE_ DCFC_evt_OverBusbarTemp 1 "Error" 0 "Normal" ;
VAL_TABLE_ DCFC_evt_E2E_Flt 1 "Error" 0 "Normal" ;
VAL_TABLE_ DCFC_evt_MIA_Flt 1 "Error" 0 "Normal" ;

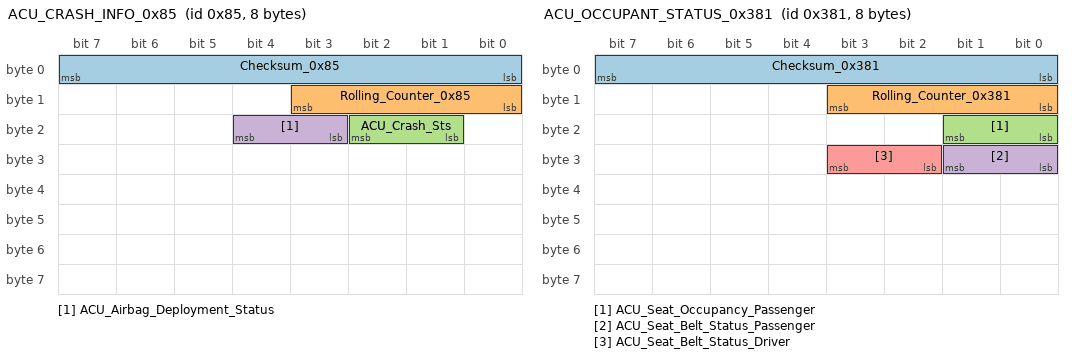
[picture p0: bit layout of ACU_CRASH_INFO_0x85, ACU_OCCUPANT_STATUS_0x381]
BO_ 133 ACU_CRASH_INFO_0x85: 8 ACU
 SG_ Checksum_0x85 : 7|8@0+ (1,0) [0|255] ""  VCU,BCM,IPC
 SG_ Rolling_Counter_0x85 : 11|4@0+ (1,0) [0|15] ""  VCU,BCM,IPC
 SG_ ACU_Crash_Sts : 18|2@0+ (1,0) [0|3] ""  VCU,BCM,IPC
 SG_ ACU_Airbag_Deployment_Status : 20|2@0+ (1,0) [0|3] ""  VCU,IPC

BO_ 897 ACU_OCCUPANT_STATUS_0x381: 8 ACU
 SG_ Checksum_0x381 : 7|8@0+ (1,0) [0|255] ""  VCU,IPC,ABS
 SG_ Rolling_Counter_0x381 : 11|4@0+ (1,0) [0|15] ""  VCU,IPC,ABS
 SG_ ACU_Seat_Occupancy_Passenger : 17|2@0+ (1,0) [0|3] ""  VCU,IPC
 SG_ ACU_Seat_Belt_Status_Passenger : 25|2@0+ (1,0) [0|3] ""  VCU,IPC
 SG_ ACU_Seat_Belt_Status_Driver : 27|2@0+ (1,0) [0|3] ""  VCU,IPC,ABS

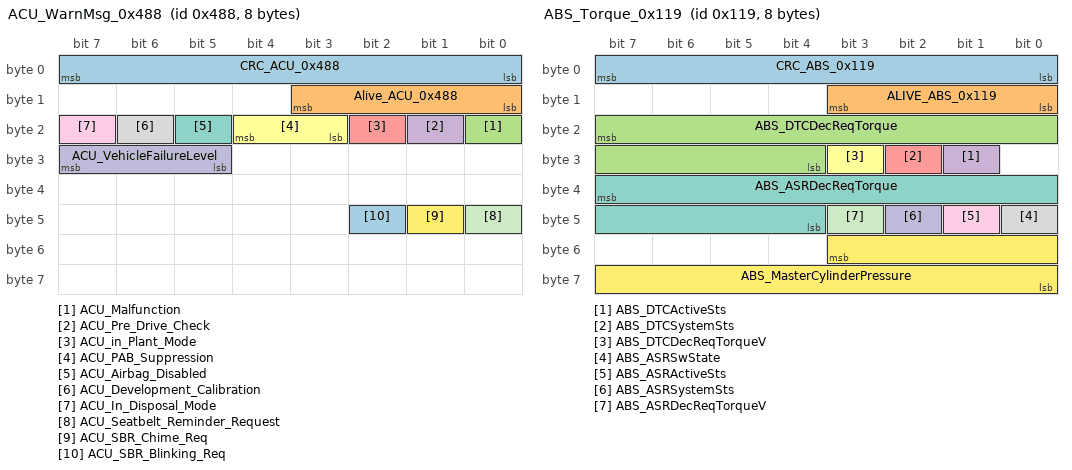
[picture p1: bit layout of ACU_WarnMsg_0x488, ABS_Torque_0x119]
BO_ 1160 ACU_WarnMsg_0x488: 8 ACU
 SG_ CRC_ACU_0x488 : 7|8@0+ (1,0) [0|255] ""  VCU,IPC
 SG_ Alive_ACU_0x488 : 11|4@0+ (1,0) [0|15] ""  VCU,IPC
 SG_ ACU_Malfunction : 16|1@0+ (1,0) [0|1] ""  VCU,IPC
 SG_ ACU_Pre_Drive_Check : 17|1@0+ (1,0) [0|1] ""  VCU,IPC
 SG_ ACU_in_Plant_Mode : 18|1@0+ (1,0) [0|1] ""  VCU,IPC
 SG_ ACU_PAB_Suppression : 20|2@0+ (1,0) [0|3] ""  VCU,IPC
 SG_ ACU_Airbag_Disabled : 21|1@0+ (1,0) [0|1] ""  VCU,IPC
 SG_ ACU_Development_Calibration : 22|1@0+ (1,0) [0|1] ""  VCU,IPC
 SG_ ACU_In_Disposal_Mode : 23|1@0+ (1,0) [0|1] ""  VCU,IPC
 SG_ ACU_VehicleFailureLevel : 31|3@0+ (1,0) [0|7] ""  VCU,IPC
 SG_ ACU_Seatbelt_Reminder_Request : 40|1@0+ (1,0) [0|1] ""  VCU,IPC
 SG_ ACU_SBR_Chime_Req : 41|1@0+ (1,0) [0|1] ""  VCU,IPC
 SG_ ACU_SBR_Blinking_Req : 42|1@0+ (1,0) [0|1] ""  VCU,IPC

BO_ 281 ABS_Torque_0x119: 8 ABS
 SG_ CRC_ABS_0x119 : 7|8@0+ (1,0) [0|255] ""  VCU
 SG_ ALIVE_ABS_0x119 : 11|4@0+ (1,0) [0|15] ""  VCU
 SG_ ABS_DTCDecReqTorque : 23|12@0+ (0.1,-200) [-200|0] "Nm"  VCU
 SG_ ABS_DTCActiveSts : 25|1@0+ (1,0) [0|1] ""  VCU
 SG_ ABS_DTCSystemSts : 26|1@0+ (1,0) [0|1] ""  VCU
 SG_ ABS_DTCDecReqTorqueV : 27|1@0+ (1,0) [0|1] ""  VCU
 SG_ ABS_ASRDecReqTorque : 39|12@0+ (0.1,0) [0|400] "Nm"  VCU
 SG_ ABS_ASRSwState : 40|1@0+ (1,0) [0|1] ""  VCU
 SG_ ABS_ASRActiveSts : 41|1@0+ (1,0) [0|1] ""  VCU
 SG_ ABS_ASRSystemSts : 42|1@0+ (1,0) [0|1] ""  VCU
 SG_ ABS_ASRDecReqTorqueV : 43|1@0+ (1,0) [0|1] ""  VCU
 SG_ ABS_MasterCylinderPressure : 51|12@0+ (1,0) [0|4094] "bar"  VCU

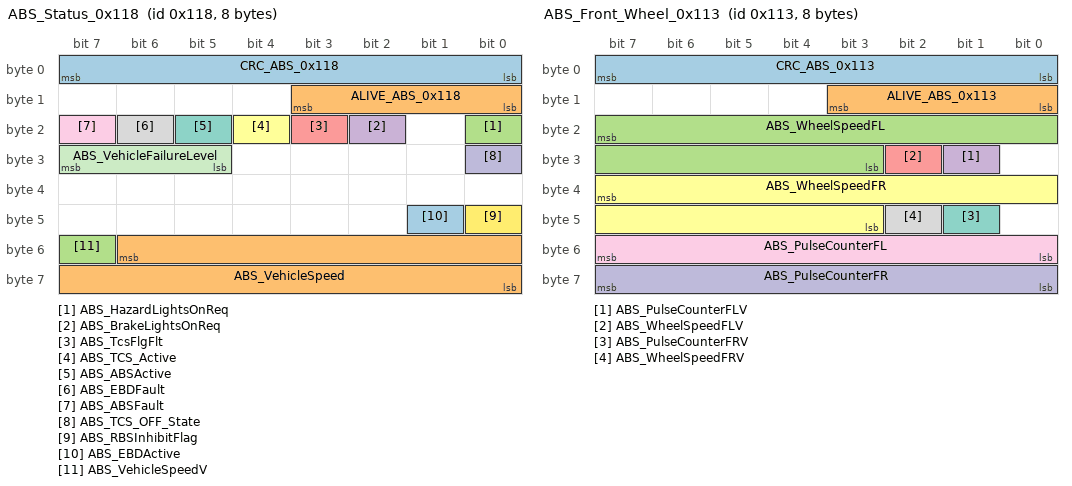
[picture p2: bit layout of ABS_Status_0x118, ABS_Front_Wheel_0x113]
BO_ 280 ABS_Status_0x118: 8 ABS
 SG_ CRC_ABS_0x118 : 7|8@0+ (1,0) [0|255] ""  VCU,BCM,SS,IPC,ACU
 SG_ ALIVE_ABS_0x118 : 11|4@0+ (1,0) [0|15] ""  VCU,BCM,SS,IPC,ACU
 SG_ ABS_HazardLightsOnReq : 16|1@0+ (1,0) [0|1] ""  VCU,BCM,SS,IPC,ACU
 SG_ ABS_BrakeLightsOnReq : 18|1@0+ (1,0) [0|1] ""  VCU,BCM,SS,IPC,ACU
 SG_ ABS_TcsFlgFlt : 19|1@0+ (1,0) [0|1] ""  VCU,BCM,SS,IPC,ACU
 SG_ ABS_TCS_Active : 20|1@0+ (1,0) [0|1] ""  VCU,BCM,SS,IPC,ACU
 SG_ ABS_ABSActive : 21|1@0+ (1,0) [0|1] ""  VCU,BCM,SS,IPC,ACU
 SG_ ABS_EBDFault : 22|1@0+ (1,0) [0|1] ""  VCU,BCM,SS,IPC,ACU
 SG_ ABS_ABSFault : 23|1@0+ (1,0) [0|1] ""  VCU,BCM,SS,IPC,ACU
 SG_ ABS_TCS_OFF_State : 24|1@0+ (1,0) [0|1] ""  VCU,BCM,SS,IPC,ACU
 SG_ ABS_VehicleFailureLevel : 31|3@0+ (1,0) [0|7] ""  VCU,BCM,SS,IPC,ACU
 SG_ ABS_RBSInhibitFlag : 40|1@0+ (1,0) [0|1] ""  VCU,BCM,SS,IPC,ACU
 SG_ ABS_EBDActive : 41|1@0+ (1,0) [0|1] ""  VCU,BCM,SS,IPC,ACU
 SG_ ABS_VehicleSpeed : 54|15@0+ (0.015625,0) [0|360] "km/h"  VCU,BCM,SS,IPC,ACU
 SG_ ABS_VehicleSpeedV : 55|1@0+ (1,0) [0|1] ""  VCU,BCM,SS,IPC,ACU

BO_ 275 ABS_Front_Wheel_0x113: 8 ABS
 SG_ CRC_ABS_0x113 : 7|8@0+ (1,0) [0|255] ""  VCU
 SG_ ALIVE_ABS_0x113 : 11|4@0+ (1,0) [0|15] ""  VCU
 SG_ ABS_WheelSpeedFL : 23|13@0+ (0.05625,0) [0|270] "km/h"  VCU
 SG_ ABS_PulseCounterFLV : 25|1@0+ (1,0) [0|1] ""  VCU
 SG_ ABS_WheelSpeedFLV : 26|1@0+ (1,0) [0|1] ""  VCU
 SG_ ABS_WheelSpeedFR : 39|13@0+ (0.05625,0) [0|270] "km/h"  VCU
 SG_ ABS_PulseCounterFRV : 41|1@0+ (1,0) [0|1] ""  VCU
 SG_ ABS_WheelSpeedFRV : 42|1@0+ (1,0) [0|1] ""  VCU
 SG_ ABS_PulseCounterFL : 55|8@0+ (1,0) [0|255] ""  VCU
 SG_ ABS_PulseCounterFR : 63|8@0+ (1,0) [0|255] ""  VCU

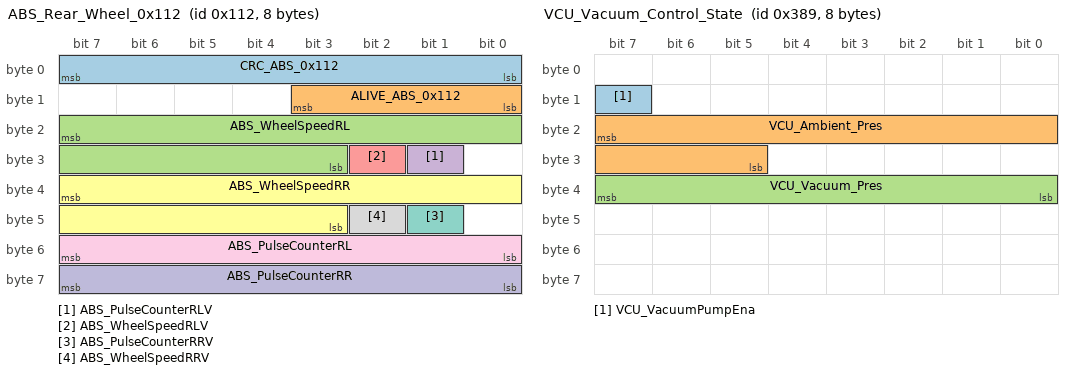
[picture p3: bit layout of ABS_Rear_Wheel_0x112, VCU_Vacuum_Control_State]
BO_ 274 ABS_Rear_Wheel_0x112: 8 ABS
 SG_ CRC_ABS_0x112 : 7|8@0+ (1,0) [0|255] ""  VCU
 SG_ ALIVE_ABS_0x112 : 11|4@0+ (1,0) [0|15] ""  VCU
 SG_ ABS_WheelSpeedRL : 23|13@0+ (0.05625,0) [0|270] "km/h"  VCU
 SG_ ABS_PulseCounterRLV : 25|1@0+ (1,0) [0|1] ""  VCU
 SG_ ABS_WheelSpeedRLV : 26|1@0+ (1,0) [0|1] ""  VCU
 SG_ ABS_WheelSpeedRR : 39|13@0+ (0.05625,0) [0|270] "km/h"  VCU
 SG_ ABS_PulseCounterRRV : 41|1@0+ (1,0) [0|1] ""  VCU
 SG_ ABS_WheelSpeedRRV : 42|1@0+ (1,0) [0|1] ""  VCU
 SG_ ABS_PulseCounterRL : 55|8@0+ (1,0) [0|255] ""  VCU
 SG_ ABS_PulseCounterRR : 63|8@0+ (1,0) [0|255] ""  VCU

BO_ 1145 VCU_Error_0x479: 8 VCU
 SG_ VCU_FaultCode : 7|8@0+ (1,0) [0|255] ""  IPC
 SG_ VCU_VehicleFailureLevel : 10|3@0+ (1,0) [0|7] ""  IPC
 SG_ VCU_EDSCAN_ERR : 16|1@0+ (1,0) [0|1] ""  IPC
 SG_ VCU_BmsCAN_ERR : 17|1@0+ (1,0) [0|1] ""  IPC
 SG_ VCU_DcdcCAN_ERR : 18|1@0+ (1,0) [0|1] ""  IPC
 SG_ VCU_AbsCAN_ERR : 19|1@0+ (1,0) [0|1] ""  IPC
 SG_ VCU_ACUCAN_ERR : 20|1@0+ (1,0) [0|1] ""  IPC
 SG_ VCU_BcmCAN_ERR_reserved : 21|1@0+ (1,0) [0|1] ""  IPC
 SG_ VCU_BrakeSys_Err : 22|1@0+ (1,0) [0|1] ""  IPC
 SG_ VCU_AccPed_ERR : 23|1@0+ (1,0) [0|1] ""  IPC
 SG_ VCU_Shift_ERR : 24|1@0+ (1,0) [0|1] ""  IPC
 SG_ VCU_EPSCAN_ERR : 25|1@0+ (1,0) [0|1] ""  IPC
 SG_ VCU_EvccCAN_ERR : 26|1@0+ (1,0) [0|1] ""  IPC
 SG_ VCU_FlgHVIL_ERR : 27|1@0+ (1,0) [0|1] ""  IPC
 SG_ VCU_ObcCAN_ERR : 41|1@0+ (1,0) [0|1] ""  IPC
 SG_ VCU_SSCAN_ERR : 39|1@0+ (1,0) [0|1] ""  IPC
 SG_ VCU_EacCAN_ERR : 38|1@0+ (1,0) [0|1] ""  IPC
 SG_ VCU_AccPedalOutRange : 40|1@0+ (1,0) [0|1] ""  IPC

BO_ 1221 VCU_Status: 8 VCU
 SG_ CRC_VCU_0x4C5 : 7|8@0+ (1,0) [0|255] ""  BCM,IPC,ABS,ACU
 SG_ ALIVE_VCU_0x4C5 : 11|4@0+ (1,0) [0|15] ""  BCM,IPC,ABS,ACU
 SG_ VCU_CreepDisable_stt : 13|1@0+ (1,0) [0|1] ""  BCM,IPC,ABS,ACU
 SG_ VCU_RDCSts : 14|1@0+ (1,0) [0|1] ""  BCM,IPC,ABS,ACU
 SG_ VCU_RBCSts : 15|1@0+ (1,0) [0|1] ""  BCM,IPC,ABS,ACU
 SG_ VCU_BrkPedalSWSts : 17|2@0+ (1,0) [0|3] ""  BCM,IPC,ABS,ACU
 SG_ Brakefluid_levelSts : 19|2@0+ (1,0) [0|3] ""  BCM,IPC,ABS,ACU
 SG_ VCU_HandBrakeSts : 20|1@0+ (1,0) [0|1] ""  BCM,IPC,ABS,ACU
 SG_ VCU_RegenLevelfeed : 21|1@0+ (1,0) [0|1] ""  BCM,IPC,ABS,ACU
 SG_ VCU_PowerLimit : 22|1@0+ (1,0) [0|1] ""  BCM,IPC,ABS,ACU
 SG_ VCU_AccPedaPosValid : 23|1@0+ (1,0) [0|1] ""  BCM,IPC,ABS,ACU
 SG_ VCU_AccPedaPos : 31|8@0+ (1,0) [0|100] "%"  BCM,IPC,ABS,ACU
 SG_ VCU_VehicleHVStatus : 33|2@0+ (1,0) [0|3] ""  BCM,IPC,ABS,ACU
 SG_ VCU_VacuumPresWrn : 35|2@0+ (1,0) [0|3] ""  BCM,IPC,ABS,ACU
 SG_ VCU_VacuumSts : 37|2@0+ (1,0) [0|3] ""  BCM,IPC,ABS,ACU
 SG_ VCU_InstantPowerConsump : 47|10@0+ (0.1,0) [0|100] "kwh/100km"  BCM,IPC,ABS,ACU
 SG_ VCU_AveragePowerConsump : 53|10@0+ (0.1,0) [0|100] "kwh/100km"  BCM,IPC,ABS,ACU
 SG_ VCU_LowSOCWarning : 56|1@0+ (1,0) [0|1] ""  BCM,IPC,ABS,ACU
 SG_ VCU_TqReductionRqstResponse : 57|1@0+ (1,0) [0|1] ""  BCM,IPC,ABS,ACU
 SG_ VCU_DrvModeSts : 59|2@0+ (1,0) [0|3] ""  BCM,IPC,ABS,ACU

BO_ 905 VCU_Vacuum_Control_State: 8 VCU
 SG_ VCU_VacuumPumpEna : 15|1@0+ (1,0) [0|1] ""  IPC
 SG_ VCU_Ambient_Pres : 23|11@0+ (0.1,0) [0|150] "kPa"  IPC
 SG_ VCU_Vacuum_Pres : 39|8@0+ (1,-150) [-150|50] "kPa"  IPC

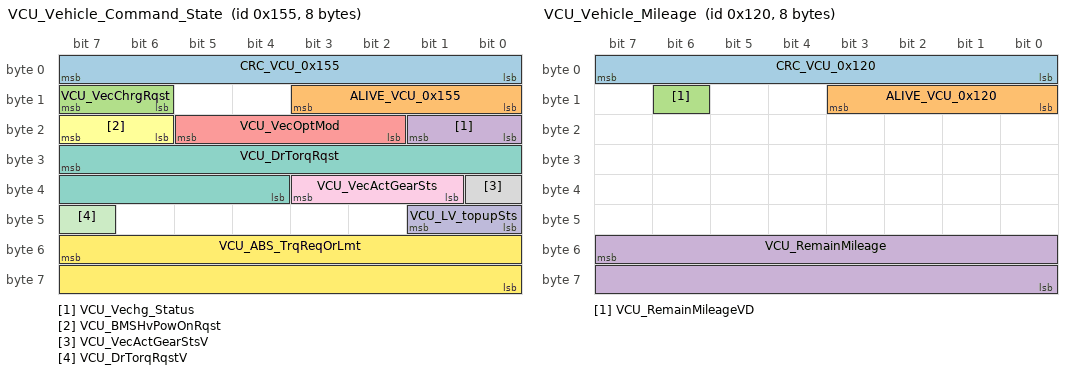
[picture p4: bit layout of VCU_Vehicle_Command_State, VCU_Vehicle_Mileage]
BO_ 341 VCU_Vehicle_Command_State: 8 VCU
 SG_ CRC_VCU_0x155 : 7|8@0+ (1,0) [0|255] ""  BCM,IPC,ABS,ACU
 SG_ ALIVE_VCU_0x155 : 11|4@0+ (1,0) [0|15] ""  BCM,IPC,ABS,ACU
 SG_ VCU_VecChrgRqst : 15|2@0+ (1,0) [0|3] ""  BCM,IPC,ABS,ACU
 SG_ VCU_Vechg_Status : 17|2@0+ (1,0) [0|3] ""  BCM,IPC,ABS,ACU
 SG_ VCU_VecOptMod : 21|4@0+ (1,0) [0|15] ""  BCM,IPC,ABS,ACU
 SG_ VCU_BMSHvPowOnRqst : 23|2@0+ (1,0) [0|3] ""  BCM,IPC,ABS,ACU
 SG_ VCU_DrTorqRqst : 31|12@0+ (0.25,-511) [-511|511] "Nm"  BCM,IPC,ABS,ACU
 SG_ VCU_VecActGearStsV : 32|1@0+ (1,0) [0|1] ""  BCM,IPC,ABS,ACU
 SG_ VCU_VecActGearSts : 35|3@0+ (1,0) [0|7] ""  BCM,IPC,ABS,ACU
 SG_ VCU_LV_topupSts : 41|2@0+ (1,0) [0|3] ""  BCM,IPC,ABS,ACU
 SG_ VCU_DrTorqRqstV : 47|1@0+ (1,0) [0|1] ""  BCM,IPC,ABS,ACU
 SG_ VCU_ABS_TrqReqOrLmt : 55|16@0+ (0.1,-2000) [-2000|2000] "Nm"  BCM,IPC,ABS,ACU

BO_ 288 VCU_Vehicle_Mileage: 8 VCU
 SG_ CRC_VCU_0x120 : 7|8@0+ (1,0) [0|255] ""  IPC
 SG_ ALIVE_VCU_0x120 : 11|4@0+ (1,0) [0|15] ""  IPC
 SG_ VCU_RemainMileageVD : 14|1@0+ (1,0) [0|1] ""  IPC
 SG_ VCU_RemainMileage : 55|16@0+ (0.1,0) [0|1000] ""  IPC

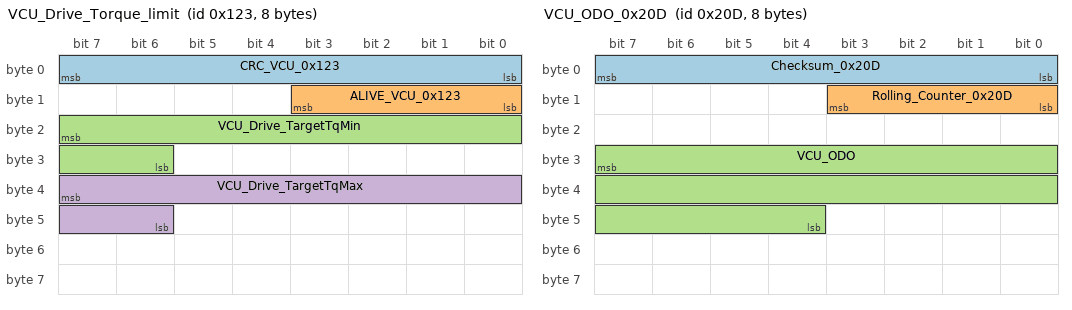
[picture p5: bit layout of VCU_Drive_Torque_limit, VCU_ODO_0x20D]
BO_ 291 VCU_Drive_Torque_limit: 8 VCU
 SG_ CRC_VCU_0x123 : 7|8@0+ (1,0) [0|255] ""  ABS
 SG_ ALIVE_VCU_0x123 : 11|4@0+ (1,0) [0|15] ""  ABS
 SG_ VCU_Drive_TargetTqMin : 23|10@0+ (1,-500) [-500|0] "Nm"  ABS
 SG_ VCU_Drive_TargetTqMax : 39|10@0+ (1,0) [0|500] "Nm"  ABS

BO_ 525 VCU_ODO_0x20D: 8 VCU
 SG_ Checksum_0x20D : 7|8@0+ (1,0) [0|255] ""  IPC
 SG_ Rolling_Counter_0x20D : 11|4@0+ (1,0) [0|15] ""  IPC
 SG_ VCU_ODO : 31|20@0+ (1,0) [0|999999] "km"  IPC

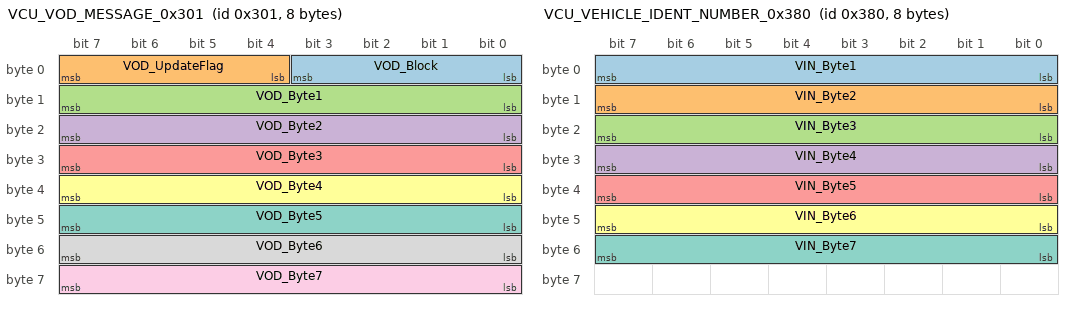
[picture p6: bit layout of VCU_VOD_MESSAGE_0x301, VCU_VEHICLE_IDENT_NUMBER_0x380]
BO_ 769 VCU_VOD_MESSAGE_0x301: 8 VCU
 SG_ VOD_Block : 3|4@0+ (1,0) [0|7] ""  IPC
 SG_ VOD_UpdateFlag : 7|4@0+ (1,0) [0|7] ""  IPC
 SG_ VOD_Byte1 : 15|8@0+ (1,0) [0|255] ""  IPC
 SG_ VOD_Byte2 : 23|8@0+ (1,0) [0|255] ""  IPC
 SG_ VOD_Byte3 : 31|8@0+ (1,0) [0|255] ""  IPC
 SG_ VOD_Byte4 : 39|8@0+ (1,0) [0|255] ""  IPC
 SG_ VOD_Byte5 : 47|8@0+ (1,0) [0|255] ""  IPC
 SG_ VOD_Byte6 : 55|8@0+ (1,0) [0|255] ""  IPC
 SG_ VOD_Byte7 : 63|8@0+ (1,0) [0|255] ""  IPC

BO_ 896 VCU_VEHICLE_IDENT_NUMBER_0x380: 8 VCU
 SG_ VIN_Byte1 : 7|8@0+ (1,0) [0|255] ""  IPC
 SG_ VIN_Byte2 : 15|8@0+ (1,0) [0|255] ""  IPC
 SG_ VIN_Byte3 : 23|8@0+ (1,0) [0|255] ""  IPC
 SG_ VIN_Byte4 : 31|8@0+ (1,0) [0|255] ""  IPC
 SG_ VIN_Byte5 : 39|8@0+ (1,0) [0|255] ""  IPC
 SG_ VIN_Byte6 : 47|8@0+ (1,0) [0|255] ""  IPC
 SG_ VIN_Byte7 : 55|8@0+ (1,0) [0|255] ""  IPC

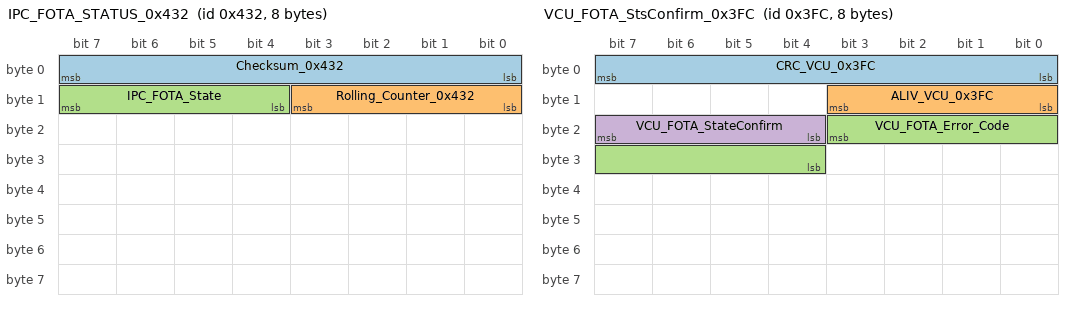
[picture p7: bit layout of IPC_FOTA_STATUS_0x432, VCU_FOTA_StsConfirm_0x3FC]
BO_ 1074 IPC_FOTA_STATUS_0x432: 8 IPC
 SG_ Checksum_0x432 : 7|8@0+ (1,0) [0|255] ""  VCU,BCM,SS,ABS,ACU
 SG_ Rolling_Counter_0x432 : 11|4@0+ (1,0) [0|15] ""  VCU,BCM,SS,ABS,ACU
 SG_ IPC_FOTA_State : 15|4@0+ (1,0) [0|14] ""  VCU,BCM,SS,ABS,ACU

BO_ 1020 VCU_FOTA_StsConfirm_0x3FC: 8 VCU
 SG_ CRC_VCU_0x3FC : 7|8@0+ (1,0) [0|255] ""  IPC
 SG_ ALIV_VCU_0x3FC : 11|4@0+ (1,0) [0|15] ""  IPC
 SG_ VCU_FOTA_Error_Code : 19|8@0+ (1,0) [0|255] ""  IPC
 SG_ VCU_FOTA_StateConfirm : 23|4@0+ (1,0) [0|14] ""  IPC

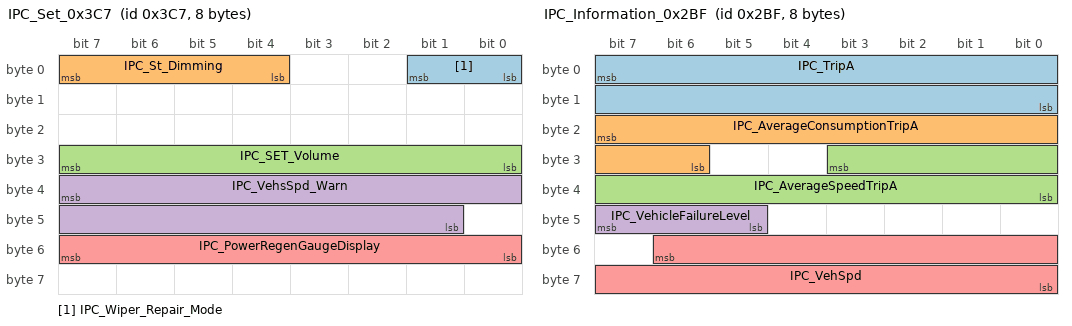
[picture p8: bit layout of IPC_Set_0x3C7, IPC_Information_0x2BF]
BO_ 967 IPC_Set_0x3C7: 8 IPC
 SG_ IPC_Wiper_Repair_Mode : 1|2@0+ (1,0) [0|3] ""  BCM,SS
 SG_ IPC_St_Dimming : 7|4@0+ (1,0) [0|15] ""  BCM,SS
 SG_ IPC_SET_Volume : 31|8@0+ (1,0) [0|32] ""  BCM
 SG_ IPC_VehsSpd_Warn : 39|15@0+ (0.01,0) [0|120] ""  BCM,SS
 SG_ IPC_PowerRegenGaugeDisplay : 55|8@0+ (1,-100) [-100|100] "%" Vector__XXX

BO_ 703 IPC_Information_0x2BF: 8 IPC
 SG_ IPC_TripA : 7|16@0+ (0.1,0) [0|999.9] "km"  VCU,BCM,ACU
 SG_ IPC_AverageConsumptionTripA : 23|10@0+ (0.1,0) [0|100] "kwh/100km"  VCU,BCM,ACU
 SG_ IPC_AverageSpeedTripA : 27|12@0+ (0.0625,0) [0|250] "km/h"  VCU,BCM,ACU
 SG_ IPC_VehicleFailureLevel : 47|3@0+ (1,0) [0|7] ""  VCU,BCM,ACU
 SG_ IPC_VehSpd : 54|15@0+ (0.01,0) [0|327.66] "kph"  VCU,BCM,ACU

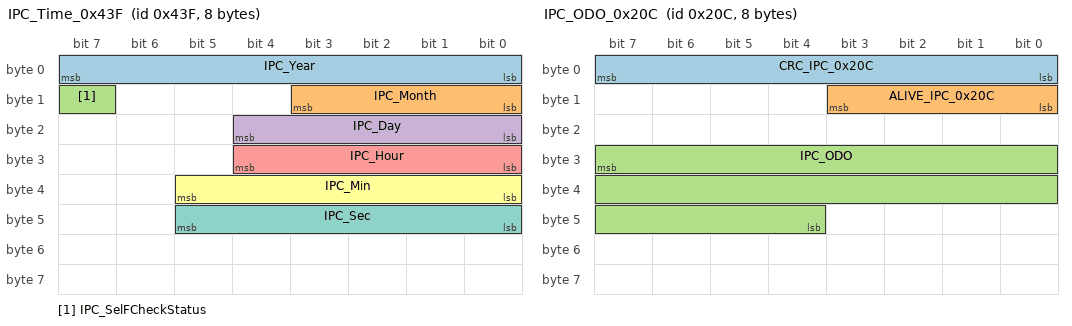
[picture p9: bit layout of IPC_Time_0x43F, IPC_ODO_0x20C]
BO_ 1087 IPC_Time_0x43F: 8 IPC
 SG_ IPC_Year : 7|8@0+ (1,2000) [2000|2255] ""  VCU,BCM,ABS,ACU
 SG_ IPC_Month : 11|4@0+ (1,0) [1|12] ""  VCU,BCM,ABS,ACU
 SG_ IPC_SelFCheckStatus : 15|1@0+ (1,0) [0|1] ""  VCU,BCM,ABS,ACU
 SG_ IPC_Day : 20|5@0+ (1,0) [1|31] ""  VCU,BCM,ABS,ACU
 SG_ IPC_Hour : 28|5@0+ (1,0) [0|31] "hour"  VCU,BCM,ABS,ACU
 SG_ IPC_Min : 37|6@0+ (1,0) [0|63] "min"  VCU,BCM,ABS,ACU
 SG_ IPC_Sec : 45|6@0+ (1,0) [0|63] "second"  VCU,BCM,ABS,ACU

BO_ 524 IPC_ODO_0x20C: 8 IPC
 SG_ CRC_IPC_0x20C : 7|8@0+ (1,0) [0|255] ""  VCU,BCM,ACU
 SG_ ALIVE_IPC_0x20C : 11|4@0+ (1,0) [0|15] ""  VCU,BCM,ACU
 SG_ IPC_ODO : 31|20@0+ (1,0) [0|999999] "km"  VCU,BCM,ACU

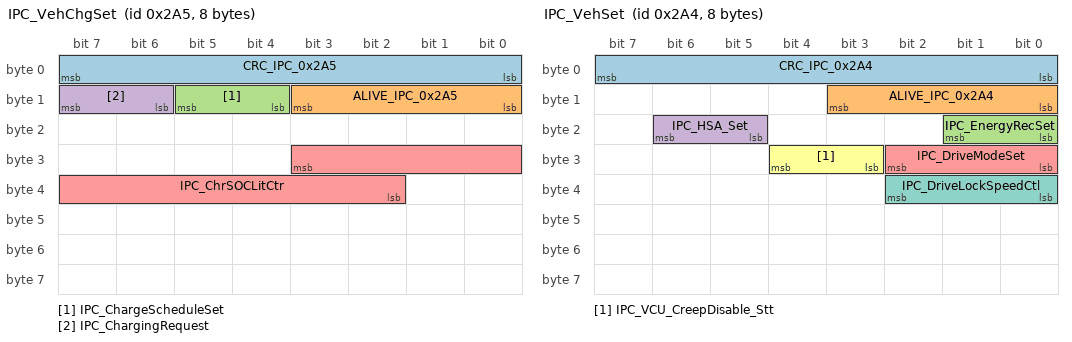
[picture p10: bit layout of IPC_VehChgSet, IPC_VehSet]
BO_ 677 IPC_VehChgSet: 8 IPC
 SG_ CRC_IPC_0x2A5 : 7|8@0+ (1,0) [0|255] ""  VCU
 SG_ ALIVE_IPC_0x2A5 : 11|4@0+ (1,0) [0|15] ""  VCU
 SG_ IPC_ChargeScheduleSet : 13|2@0+ (1,0) [0|3] ""  VCU
 SG_ IPC_ChargingRequest : 15|2@0+ (1,0) [0|3] ""  VCU
 SG_ IPC_ChrSOCLitCtr : 27|10@0+ (0.1,0) [0|1000] "%"  VCU

BO_ 676 IPC_VehSet: 8 IPC
 SG_ CRC_IPC_0x2A4 : 7|8@0+ (1,0) [0|255] ""  VCU,BCM
 SG_ ALIVE_IPC_0x2A4 : 11|4@0+ (1,0) [0|15] ""  VCU,BCM
 SG_ IPC_EnergyRecSet : 17|2@0+ (1,0) [0|3] ""  VCU,BCM
 SG_ IPC_HSA_Set : 22|2@0+ (1,0) [0|3] ""  VCU
 SG_ IPC_DriveModeSet : 26|3@0+ (1,0) [0|7] ""  VCU,BCM
 SG_ IPC_VCU_CreepDisable_Stt : 28|2@0+ (1,0) [0|3] ""  VCU,BCM
 SG_ IPC_DriveLockSpeedCtl : 34|3@0+ (1,0) [0|7] ""  VCU,BCM

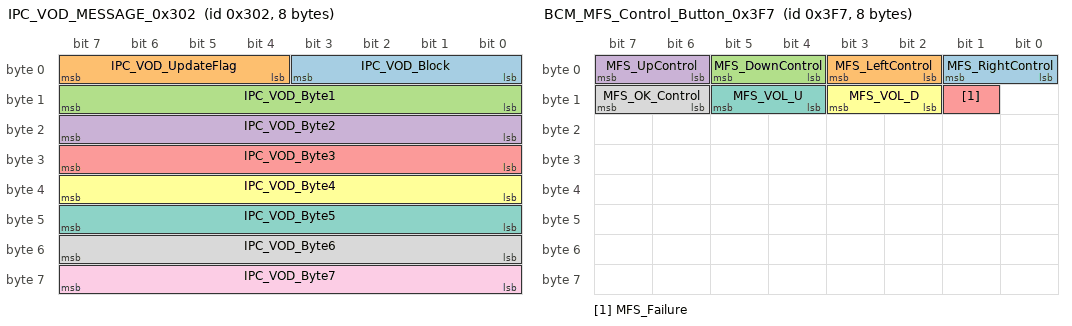
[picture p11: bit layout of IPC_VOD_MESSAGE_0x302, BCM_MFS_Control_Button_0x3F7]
BO_ 770 IPC_VOD_MESSAGE_0x302: 8 IPC
 SG_ IPC_VOD_Block : 3|4@0+ (1,0) [0|7] ""  VCU
 SG_ IPC_VOD_UpdateFlag : 7|4@0+ (1,0) [0|7] ""  VCU
 SG_ IPC_VOD_Byte1 : 15|8@0+ (1,0) [0|255] ""  VCU
 SG_ IPC_VOD_Byte2 : 23|8@0+ (1,0) [0|255] ""  VCU
 SG_ IPC_VOD_Byte3 : 31|8@0+ (1,0) [0|255] ""  VCU
 SG_ IPC_VOD_Byte4 : 39|8@0+ (1,0) [0|255] ""  VCU
 SG_ IPC_VOD_Byte5 : 47|8@0+ (1,0) [0|255] ""  VCU
 SG_ IPC_VOD_Byte6 : 55|8@0+ (1,0) [0|255] ""  VCU
 SG_ IPC_VOD_Byte7 : 63|8@0+ (1,0) [0|255] ""  VCU

BO_ 1015 BCM_MFS_Control_Button_0x3F7: 8 BCM
 SG_ MFS_RightControl : 1|2@0+ (1,0) [0|3] ""  IPC
 SG_ MFS_LeftControl : 3|2@0+ (1,0) [0|3] ""  IPC
 SG_ MFS_DownControl : 5|2@0+ (1,0) [0|3] ""  IPC
 SG_ MFS_UpControl : 7|2@0+ (1,0) [0|3] ""  IPC
 SG_ MFS_Failure : 9|1@0+ (1,0) [0|1] ""  IPC
 SG_ MFS_VOL_D : 11|2@0+ (1,0) [0|3] ""  IPC
 SG_ MFS_VOL_U : 13|2@0+ (1,0) [0|3] ""  IPC
 SG_ MFS_OK_Control : 15|2@0+ (1,0) [0|3] ""  IPC

BO_ 264 SS_DriveReq_0x108: 8 SS
 SG_ Checksum_0x108 : 7|8@0+ (1,0) [0|255] ""  VCU,BCM,IPC
 SG_ Rolling_Counter_0x108 : 11|4@0+ (1,0) [0|15] ""  VCU,BCM,IPC
 SG_ SS_DriveModeReq_reserved : 16|1@0+ (1,0) [0|1] ""  VCU,BCM,IPC
 SG_ SS_TargetGearReq : 23|3@0+ (1,0) [0|7] ""  VCU,BCM,IPC
 SG_ SS_Fault : 27|4@0+ (1,0) [0|15] ""  VCU,BCM,IPC
 SG_ FR_Wipercontrol_switch : 34|3@0+ (1,0) [0|7] ""  VCU,BCM,IPC
 SG_ Front_Wash : 36|2@0+ (1,0) [0|3] ""  VCU,BCM,IPC
 SG_ SS_FogLight_reserved : 37|1@0+ (1,0) [0|1] ""  VCU,BCM,IPC
 SG_ RR_Wiper : 39|2@0+ (1,0) [0|3] ""  VCU,BCM,IPC
 SG_ SS_lane_change_lampSts : 41|2@0+ (1,0) [0|3] ""  VCU,BCM,IPC
 SG_ SS_Overtaking_lamp : 42|1@0+ (1,0) [0|1] ""  VCU,BCM,IPC
 SG_ SS_TurnIndicatorSts : 44|2@0+ (1,0) [0|3] ""  VCU,BCM,IPC
 SG_ SS_PosLmpSts : 45|1@0+ (1,0) [0|1] ""  VCU,BCM,IPC
 SG_ SS_LowBeamSts : 46|1@0+ (1,0) [0|1] ""  VCU,BCM,IPC
 SG_ SS_HighBeamSts : 47|1@0+ (1,0) [0|1] ""  VCU,BCM,IPC
 SG_ SS_HardNumLow : 51|4@0+ (1,0) [0|15] ""  VCU,BCM,IPC
 SG_ SS_HardNumHigh : 55|4@0+ (1,0) [0|15] ""  VCU,BCM,IPC
 SG_ SS_SoftNumLow : 59|4@0+ (1,0) [0|15] ""  VCU,BCM,IPC
 SG_ SS_SoftNumHigh : 63|4@0+ (1,0) [0|15] ""  VCU,BCM,IPC

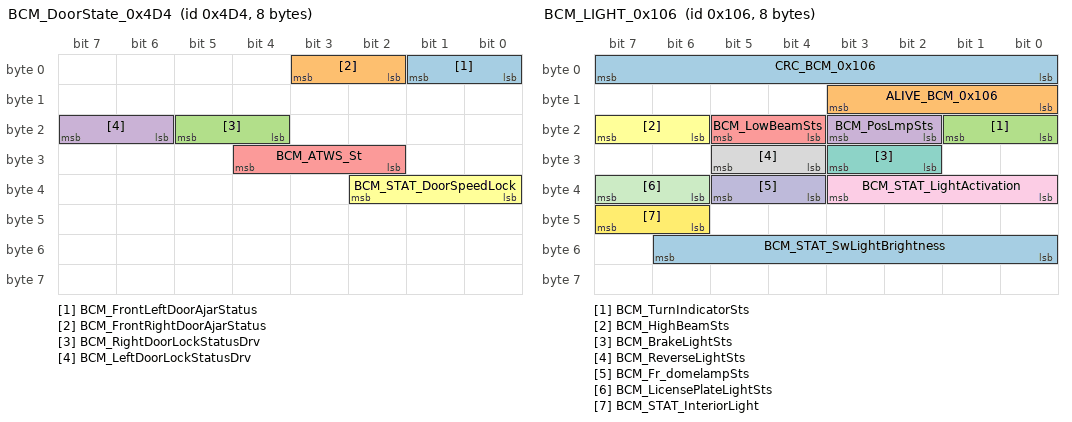
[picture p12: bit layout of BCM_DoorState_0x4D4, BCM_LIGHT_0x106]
BO_ 1236 BCM_DoorState_0x4D4: 8 BCM
 SG_ BCM_FrontLeftDoorAjarStatus : 1|2@0+ (1,0) [0|1] ""  VCU,IPC
 SG_ BCM_FrontRightDoorAjarStatus : 3|2@0+ (1,0) [0|1] ""  VCU,IPC
 SG_ BCM_RightDoorLockStatusDrv : 21|2@0+ (1,0) [0|3] ""  VCU,IPC
 SG_ BCM_LeftDoorLockStatusDrv : 23|2@0+ (1,0) [0|3] ""  VCU,IPC
 SG_ BCM_ATWS_St : 28|3@0+ (1,0) [0|7] ""  VCU,IPC
 SG_ BCM_STAT_DoorSpeedLock : 34|3@0+ (1,0) [0|7] ""  VCU,IPC

BO_ 262 BCM_LIGHT_0x106: 8 BCM
 SG_ CRC_BCM_0x106 : 7|8@0+ (1,0) [0|255] ""  VCU,IPC,ACU
 SG_ ALIVE_BCM_0x106 : 11|4@0+ (1,0) [0|15] ""  VCU,IPC,ACU
 SG_ BCM_TurnIndicatorSts : 17|2@0+ (1,0) [0|3] ""  VCU,IPC,ACU
 SG_ BCM_PosLmpSts : 19|2@0+ (1,0) [0|3] ""  VCU,IPC,ACU
 SG_ BCM_LowBeamSts : 21|2@0+ (1,0) [0|3] ""  VCU,IPC,ACU
 SG_ BCM_HighBeamSts : 23|2@0+ (1,0) [0|3] ""  VCU,IPC,ACU
 SG_ BCM_BrakeLightSts : 27|2@0+ (1,0) [0|3] ""  VCU,IPC,ACU
 SG_ BCM_ReverseLightSts : 29|2@0+ (1,0) [0|3] ""  VCU,IPC,ACU
 SG_ BCM_STAT_LightActivation : 35|4@0+ (1,0) [0|7] ""  VCU,IPC,ACU
 SG_ BCM_Fr_domelampSts : 37|2@0+ (1,0) [0|3] ""  VCU,IPC,ACU
 SG_ BCM_LicensePlateLightSts : 39|2@0+ (1,0) [0|3] ""  VCU,IPC,ACU
 SG_ BCM_STAT_InteriorLight : 47|2@0+ (1,0) [0|3] ""  VCU,IPC,ACU
 SG_ BCM_STAT_SwLightBrightness : 54|7@0+ (1,0) [0|100] "%"  VCU,IPC,ACU

BO_ 513 BCM_Status_0x201: 8 BCM
 SG_ CRC_BCM_0x201 : 7|8@0+ (1,0) [0|255] ""  VCU,SS,IPC,ABS,ACU
 SG_ ALIVE_BCM_0x201 : 11|4@0+ (1,0) [0|15] ""  VCU,SS,IPC,ABS,ACU
 SG_ BCM_LV_topupReq : 15|4@0+ (1,0) [0|3] ""  VCU,SS,IPC,ABS,ACU
 SG_ BCM_BatteryVoltage : 23|8@0+ (0.1,0) [0|25.4] "V"  VCU,SS,IPC,ABS,ACU
 SG_ BCM_Key_CheckSts : 24|1@0+ (1,0) [0|1] ""  VCU,SS,IPC,ABS,ACU
 SG_ BCM_Press_BrkPedal_Alert : 25|1@0+ (1,0) [0|1] ""  VCU,SS,IPC,ABS,ACU
 SG_ BCM_EmergencyStop : 27|2@0+ (1,0) [0|3] ""  VCU,SS,IPC,ABS,ACU
 SG_ BCM_IGN1RelayOutputSts : 29|2@0+ (1,0) [0|3] ""  VCU,SS,IPC,ABS,ACU
 SG_ BCM_ACCRelayOutputSts : 31|2@0+ (1,0) [0|3] ""  VCU,SS,IPC,ABS,ACU
 SG_ BCM_FLWIN_Postion_Reserved : 34|3@0+ (1,0) [0|7] ""  VCU,SS,IPC,ABS,ACU
 SG_ BCM_KEY_MatchSts : 36|2@0+ (1,0) [0|3] ""  VCU,SS,IPC,ABS,ACU
 SG_ BCM_FRWIN_Postion_Reserved : 39|3@0+ (1,0) [0|7] ""  VCU,SS,IPC,ABS,ACU
 SG_ BCM_BCMFaultCode : 47|8@0+ (1,0) [0|255] ""  VCU,SS,IPC,ABS,ACU
 SG_ BCM_PowerMode : 49|2@0+ (1,0) [0|3] ""  VCU,SS,IPC,ABS,ACU
 SG_ BCM_BrakeSwSts : 51|2@0+ (1,0) [0|3] ""  VCU,SS,IPC,ABS,ACU
 SG_ BCM_VehicleFailureLevel : 55|3@0+ (1,0) [0|7] ""  VCU,SS,IPC,ABS,ACU
 SG_ BCM_Anti_theftAlarmSetSts : 57|2@0+ (1,0) [0|3] ""  VCU,SS,IPC,ABS,ACU
 SG_ BCM_FMH_SetSts : 59|2@0+ (1,0) [0|3] ""  VCU,SS,IPC,ABS,ACU
 SG_ BCM_IGN1RelayFaultSts : 61|2@0+ (1,0) [0|3] ""  VCU,SS,IPC,ABS,ACU
 SG_ BCM_ACCRelayFaultSts : 63|2@0+ (1,0) [0|3] ""  VCU,SS,IPC,ABS,ACU

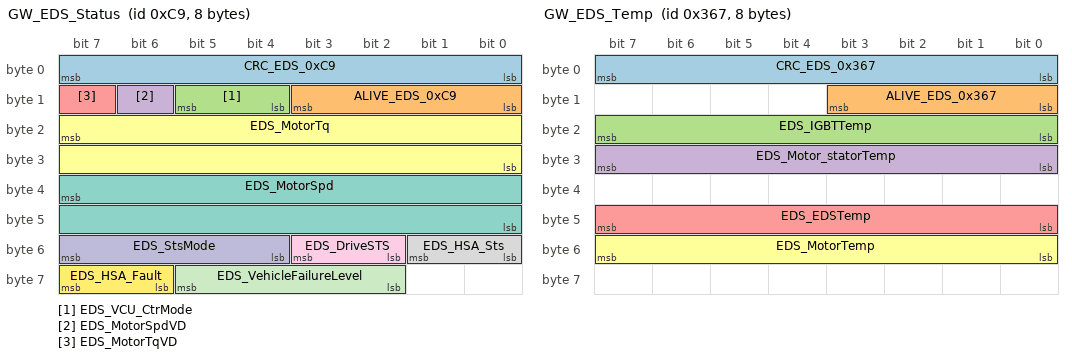
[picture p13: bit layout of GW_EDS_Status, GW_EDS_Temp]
BO_ 201 GW_EDS_Status: 8 VCU
 SG_ CRC_EDS_0xC9 : 7|8@0+ (1,0) [0|255] ""  IPC,ABS,ACU
 SG_ ALIVE_EDS_0xC9 : 11|4@0+ (1,0) [0|15] ""  IPC,ABS,ACU
 SG_ EDS_VCU_CtrMode : 13|2@0+ (1,0) [0|3] ""  IPC,ABS,ACU
 SG_ EDS_MotorSpdVD : 14|1@0+ (1,0) [0|1] ""  IPC,ABS,ACU
 SG_ EDS_MotorTqVD : 15|1@0+ (1,0) [0|1] ""  IPC,ABS,ACU
 SG_ EDS_MotorTq : 23|16@0+ (0.1,-1200) [-1200|1200] "Nm"  IPC,ABS,ACU
 SG_ EDS_MotorSpd : 39|16@0+ (1,-20000) [-20000|45531] "rpm"  IPC,ABS,ACU
 SG_ EDS_HSA_Sts : 49|2@0+ (1,0) [0|3] ""  IPC
 SG_ EDS_DriveSTS : 51|2@0+ (1,0) [0|3] ""  IPC,ABS,ACU
 SG_ EDS_StsMode : 55|4@0+ (1,0) [0|15] ""  IPC,ABS,ACU
 SG_ EDS_VehicleFailureLevel : 61|4@0+ (1,0) [0|7] ""  IPC,ABS,ACU
 SG_ EDS_HSA_Fault : 63|2@0+ (1,0) [0|3] ""  IPC

BO_ 871 GW_EDS_Temp: 8 VCU
 SG_ CRC_EDS_0x367 : 7|8@0+ (1,0) [0|255] ""  IPC
 SG_ ALIVE_EDS_0x367 : 11|4@0+ (1,0) [0|15] ""  IPC
 SG_ EDS_IGBTTemp : 23|8@0+ (1,-40) [-40|210] ""  IPC
 SG_ EDS_Motor_statorTemp : 31|8@0+ (1,-40) [-40|210] ""  IPC
 SG_ EDS_EDSTemp : 47|8@0+ (1,-40) [-40|210] ""  IPC
 SG_ EDS_MotorTemp : 55|8@0+ (1,-40) [-40|210] ""  IPC

CM_ SG_ 133 Checksum_0x85 "Checksum";
CM_ SG_ 133 Rolling_Counter_0x85 "Rolling Counter";
CM_ SG_ 133 ACU_Crash_Sts "Crash status";
CM_ SG_ 133 ACU_Airbag_Deployment_Status "Signal to indicate if airbag/pretensioner/pyrofuse is deployed";
CM_ SG_ 897 Checksum_0x381 "Checksum";
CM_ SG_ 897 Rolling_Counter_0x381 "Rolling Counter";
CM_ SG_ 897 ACU_Seat_Occupancy_Passenger "Signal to indicate status of occupancy";
CM_ SG_ 897 ACU_Seat_Belt_Status_Passenger "Seatbelt status for seatbelt reminder function";
CM_ SG_ 897 ACU_Seat_Belt_Status_Driver "Seatbelt status for seatbelt reminder function";
CM_ SG_ 1160 CRC_ACU_0x488 "Checksum";
CM_ SG_ 1160 Alive_ACU_0x488 "Rolling Counter";
CM_ SG_ 1160 ACU_Malfunction "ACU Malfunction (trigger airbag warning lamp)";
CM_ SG_ 1160 ACU_Pre_Drive_Check "ACU status after pre-drive check (trigger airbag warning lamp if any failure)";
CM_ SG_ 1160 ACU_in_Plant_Mode "ACU plant mode status (trigger airbag warning lamp)";
CM_ SG_ 1160 ACU_PAB_Suppression "ACU suppress passenger airbag (front AB 1st stage, front AB 2nd stage, knee AB). This is used to trigger PAB indicator in IPC's display.";
CM_ SG_ 1160 ACU_Airbag_Disabled "ACU airbag disabled status due to Algo disabled or Firing disabled due to diagnostic or inert calibration file is flashed (trigger Airbag warning lamp when airbag is disabled)";
CM_ SG_ 1160 ACU_Development_Calibration "ACU calibration file status indicate whether ACU is flashed with calibration file for development purpose only (trigger Airbag warning lamp and chime when ACU is flashed with development calibration file)";
CM_ SG_ 1160 ACU_In_Disposal_Mode "ACU disposal mode status (trigger airbag warning lamp when ACU in disposal mode)";
CM_ SG_ 1160 ACU_VehicleFailureLevel "ACU Vehicle failure levelACU整车故障等级";
CM_ SG_ 1160 ACU_Seatbelt_Reminder_Request "ACU request seatbelt reminder (1 signal for whole front and rear seats)";
CM_ SG_ 1160 ACU_SBR_Chime_Req "ACU request chime to IPC for seatbelt reminder front row";
CM_ SG_ 1160 ACU_SBR_Blinking_Req "ACU send blinking request to IPC (trigger blinking of seatbelt reminder lamp)";
CM_ SG_ 281 CRC_ABS_0x119 "CRC_ABS_0x119校验和";
CM_ SG_ 281 ALIVE_ABS_0x119 "ALIVE_ABS_0x119循环计数";
CM_ SG_ 281 ABS_DTCDecReqTorque "DTC Torque control requests a torque valueDTC扭矩控制请求扭矩值";
CM_ SG_ 281 ABS_DTCActiveSts "DTC activation statusDTC激活状态";
CM_ SG_ 281 ABS_DTCSystemSts "DTC system statusDTC系统状态";
CM_ SG_ 281 ABS_DTCDecReqTorqueV "DTC Torque control requests torque value validityDTC扭矩控制请求扭矩值有效性";
CM_ SG_ 281 ABS_ASRDecReqTorque "ASR request torque valueASR请求扭矩值";
CM_ SG_ 281 ABS_ASRSwState "ASR switch statusASR开关状态";
CM_ SG_ 281 ABS_ASRActiveSts "ASR activation statusASR激活状态";
CM_ SG_ 281 ABS_ASRSystemSts "ASR System statusASR系统状态";
CM_ SG_ 281 ABS_ASRDecReqTorqueV "ASR request torque value validityASR请求扭矩值有效性";
CM_ SG_ 281 ABS_MasterCylinderPressure "Master cylinder pressureABS主缸压力";
CM_ SG_ 280 CRC_ABS_0x118 "CRC_ABS_0x118校验和";
CM_ SG_ 280 ALIVE_ABS_0x118 "ALIVE_ABS_0x118循环计数";
CM_ SG_ 280 ABS_HazardLightsOnReq "ABS Request to light hazard warning lights (reserved)ABS请求点亮危险警报灯（预留）";
CM_ SG_ 280 ABS_BrakeLightsOnReq "ABS request to light brake light (reserved)";
CM_ SG_ 280 ABS_TcsFlgFlt "Detect the TCS Function Fault status";
CM_ SG_ 280 ABS_TCS_Active "Indicate TCS  Function is active or not";
CM_ SG_ 280 ABS_ABSActive "ABS active stateABS激活状态";
CM_ SG_ 280 ABS_EBDFault "EBD system FailureEBD系统故障";
CM_ SG_ 280 ABS_ABSFault "ABS system FailureABS系统故障";
CM_ SG_ 280 ABS_TCS_OFF_State "Indicate the TCS Function open or close";
CM_ SG_ 280 ABS_VehicleFailureLevel "ABS Vehicle failure levelABS整车故障等级";
CM_ SG_ 280 ABS_RBSInhibitFlag "Energy recovery prohibited Flag bit能量回收禁止标志位";
CM_ SG_ 280 ABS_EBDActive "EBD activation statusEBD激活状态";
CM_ SG_ 280 ABS_VehicleSpeed "Speed";
CM_ SG_ 280 ABS_VehicleSpeedV "Speed signal validity";
CM_ SG_ 275 CRC_ABS_0x113 "CRC_ABS_0x113";
CM_ SG_ 275 ALIVE_ABS_0x113 "ALIVE_ABS_0x113";
CM_ SG_ 275 ABS_WheelSpeedFL "Current Raw wheel speed information of front left wheel.";
CM_ SG_ 275 ABS_PulseCounterFLV "front left wheel pluse counter valid";
CM_ SG_ 275 ABS_WheelSpeedFLV "Current Raw wheel speed information valid flag of front left wheel.";
CM_ SG_ 275 ABS_WheelSpeedFR "Current Raw wheel speed information of front right wheel.";
CM_ SG_ 275 ABS_PulseCounterFRV "front right wheel pluse counter valid";
CM_ SG_ 275 ABS_WheelSpeedFRV "Current Raw wheel speed information valid flag of front right wheel.";
CM_ SG_ 275 ABS_PulseCounterFL "front left wheel pluse counter";
CM_ SG_ 275 ABS_PulseCounterFR "front rightwheel pluse counter";
CM_ SG_ 274 CRC_ABS_0x112 "CRC_ABS_0x112";
CM_ SG_ 274 ALIVE_ABS_0x112 "ALIVE_ABS_0x112";
CM_ SG_ 274 ABS_WheelSpeedRL "Current Raw wheel speed information of rear left wheel.";
CM_ SG_ 274 ABS_PulseCounterRLV "rear left wheel pluse counter valid";
CM_ SG_ 274 ABS_WheelSpeedRLV "Current Raw wheel speed information valid flag of rear left wheel.";
CM_ SG_ 274 ABS_WheelSpeedRR "Current Raw wheel speed information of rear right wheel.";
CM_ SG_ 274 ABS_PulseCounterRRV "rear right wheel pluse counter valid";
CM_ SG_ 274 ABS_WheelSpeedRRV "Current Raw wheel speed information valid flag of rear right wheel";
CM_ SG_ 274 ABS_PulseCounterRL "rear left wheel pluse counter";
CM_ SG_ 274 ABS_PulseCounterRR "rear right wheel pluse counter";
CM_ SG_ 1145 VCU_FaultCode "VCU Fault Code";
CM_ SG_ 1145 VCU_VehicleFailureLevel "VehicleFaultLevel";
CM_ SG_ 1145 VCU_EDSCAN_ERR "EDS CAN Communication Error(lost EDS node)";
CM_ SG_ 1145 VCU_BmsCAN_ERR "BMS CAN Communication(LossBMSNote)";
CM_ SG_ 1145 VCU_DcdcCAN_ERR "DCDC communication Failure(lost DCDC node)";
CM_ SG_ 1145 VCU_AbsCAN_ERR "ABS communication Failure(lost ABS node)";
CM_ SG_ 1145 VCU_ACUCAN_ERR "ACU communication Failure(lost ACU node)";
CM_ SG_ 1145 VCU_BcmCAN_ERR_reserved "BCM communication Failure(lost BCM node)";
CM_ SG_ 1145 VCU_BrakeSys_Err "Brake system Failure (Reserved)";
CM_ SG_ 1145 VCU_AccPed_ERR "Throttle pedal malFunction";
CM_ SG_ 1145 VCU_Shift_ERR "Gear Shift fault";
CM_ SG_ 1145 VCU_EPSCAN_ERR "EPS Module Failure";
CM_ SG_ 1145 VCU_EvccCAN_ERR "EVCC communication failure(lost EVCC node)";
CM_ SG_ 1145 VCU_FlgHVIL_ERR "HVIL Failure";
CM_ SG_ 1145 VCU_ObcCAN_ERR "OBC  communication failure(lost OBC  node)";
CM_ SG_ 1145 VCU_SSCAN_ERR "SS communication Failure(lost SS node)";
CM_ SG_ 1145 VCU_EacCAN_ERR "EAC Module Failure";
CM_ SG_ 1145 VCU_AccPedalOutRange "Accelerator pedal over range fault";
CM_ SG_ 1221 CRC_VCU_0x4C5 "CRC_VCU_0x4C5校验";
CM_ SG_ 1221 ALIVE_VCU_0x4C5 "ALIVE_VCU_0x4C5循环计数";
CM_ SG_ 1221 VCU_CreepDisable_stt "Feedback for Creep disable request";
CM_ SG_ 1221 VCU_RDCSts "Regenerative coasted";
CM_ SG_ 1221 VCU_RBCSts "Regenerative Braking";
CM_ SG_ 1221 VCU_BrkPedalSWSts "Brake switch condition 制动开关状态";
CM_ SG_ 1221 Brakefluid_levelSts "Brakefluid_levelSts制动液位状态";
CM_ SG_ 1221 VCU_HandBrakeSts "VCU send hand brake sts   机械手刹状态";
CM_ SG_ 1221 VCU_RegenLevelfeed "VCU current regen stats";
CM_ SG_ 1221 VCU_PowerLimit "Vehicle power limit";
CM_ SG_ 1221 VCU_AccPedaPosValid "Accelerator pedal position valid加速踏板位置有效性";
CM_ SG_ 1221 VCU_AccPedaPos "Accelerator pedal position   加速踏板位置";
CM_ SG_ 1221 VCU_VehicleHVStatus "Vehicle high pressure condition      整车高压状态";
CM_ SG_ 1221 VCU_VacuumPresWrn "The warm state of Vacuum 真空度状态";
CM_ SG_ 1221 VCU_VacuumSts "The leak state of vacuume  真空泄漏状态";
CM_ SG_ 1221 VCU_InstantPowerConsump "Instant power consumption";
CM_ SG_ 1221 VCU_AveragePowerConsump "Average power comsumption";
CM_ SG_ 1221 VCU_LowSOCWarning "Low SOC WarningsVCU VCU低电量警告";
CM_ SG_ 1221 VCU_TqReductionRqstResponse "Indicate the response for the RBS/TCS request torque DTC/ASR";
CM_ SG_ 1221 VCU_DrvModeSts "Vehicle Driving Mode   整车驾驶模式";
CM_ SG_ 905 VCU_VacuumPumpEna "Vacuum pump enable flag";
CM_ SG_ 905 VCU_Ambient_Pres "indicate Ambient Pressure";
CM_ SG_ 905 VCU_Vacuum_Pres "indicate Vacuum Tank Pressure";
CM_ SG_ 341 CRC_VCU_0x155 "CRC_VCU_0x155校验";
CM_ SG_ 341 ALIVE_VCU_0x155 "ALIVE_VCU_0x155循环计数";
CM_ SG_ 341 VCU_VecChrgRqst "Vehicle charging request整车充电请求";
CM_ SG_ 341 VCU_Vechg_Status "Vehicle charging state整车充电状态";
CM_ SG_ 341 VCU_VecOptMod "Vehicle operation mode整车运行模式";
CM_ SG_ 341 VCU_BMSHvPowOnRqst "VCU_BMSHvPowOnRqst电池高压上下电指令";
CM_ SG_ 341 VCU_DrTorqRqst "Drive torque request for EDS驱动扭矩请求";
CM_ SG_ 341 VCU_VecActGearStsV "Vehicle actual gear availability 整车实际档位有效性";
CM_ SG_ 341 VCU_VecActGearSts "Current actual gear state oF the vehicle   整车当前实际档位状态";
CM_ SG_ 341 VCU_LV_topupSts "LV_topupSts  低压补电状态";
CM_ SG_ 341 VCU_DrTorqRqstV "Drive torque request validity";
CM_ SG_ 341 VCU_ABS_TrqReqOrLmt "Driver requested torque for ABS";
CM_ SG_ 288 CRC_VCU_0x120 "CheckSum";
CM_ SG_ 288 ALIVE_VCU_0x120 "RollingCounter";
CM_ SG_ 288 VCU_RemainMileageVD "Range effectiveness";
CM_ SG_ 288 VCU_RemainMileage "Range";
CM_ SG_ 291 CRC_VCU_0x123 "CRC_VCU_0xAB";
CM_ SG_ 291 ALIVE_VCU_0x123 "ALIVE_VCU_0xAB";
CM_ SG_ 291 VCU_Drive_TargetTqMin "Min Target torque for driving";
CM_ SG_ 291 VCU_Drive_TargetTqMax "Max Target torque for driving";
CM_ SG_ 525 Checksum_0x20D "Checksum";
CM_ SG_ 525 Rolling_Counter_0x20D "Rolling_Counter";
CM_ SG_ 525 VCU_ODO "odograph";
CM_ SG_ 896 VIN_Byte1 "This signal contains the seventh last digit of the chassis number";
CM_ SG_ 896 VIN_Byte2 "This signal contains the sixth last digit of the chassis number";
CM_ SG_ 896 VIN_Byte3 "This signal contains the fifth last digit of the chassis number";
CM_ SG_ 896 VIN_Byte4 "This signal contains the fourth last digit of the chassis number";
CM_ SG_ 896 VIN_Byte5 "This signal contains the third last digit of the chassis number";
CM_ SG_ 896 VIN_Byte6 "This signal contains the penultimate digit of the chassis number";
CM_ SG_ 896 VIN_Byte7 "This signal contains the last digit of the chassis number";
CM_ SG_ 1074 Checksum_0x432 "Checksum";
CM_ SG_ 1074 Rolling_Counter_0x432 "Rolling_Counter";
CM_ SG_ 1074 IPC_FOTA_State "0 ''INIT''1 ''NORMAL''2 ''FOTA FLASHING''3 ''Reserved''4 ''FAIL-SAFE-ERROR''5 ''Reserved''6 ''REMOTE DIAGNOSTICS''7 ''Invalid''";
CM_ SG_ 1020 CRC_VCU_0x3FC "Checksum";
CM_ SG_ 1020 ALIV_VCU_0x3FC "Rolling_Counter";
CM_ SG_ 1020 VCU_FOTA_Error_Code "0 ''Bit 0'' : VehSpd error = ''1''1 ''Bit 1'' : SysVoltage error = ''1''2 ''Bit 2'' : Request state error = ''1''3 ''Bit 3'' : OBD port in active = ''1''4 ''Bit 4'' : Reserved5 ''Bit 5'' : Reserved6 ''Bit 6'' : Reserved7 ''Bit 7'' : Reserved";
CM_ SG_ 1020 VCU_FOTA_StateConfirm "0 ''INIT''1 ''NORMAL''2 ''FOTA FLASHING''3 ''Reserved''4 ''FAIL-SAFE-ERROR''5 ''Reserved''6 ''REMOTE DIAGNOSTICS''7 ''Invalid''";
CM_ SG_ 967 IPC_Wiper_Repair_Mode "Wiper Repair Mode";
CM_ SG_ 967 IPC_St_Dimming "IPC  Background lump level setting to IPC";
CM_ SG_ 967 IPC_SET_Volume "IPC SET IPC volume";
CM_ SG_ 967 IPC_VehsSpd_Warn "IPC  To Configure  OverSpeed Threshold";
CM_ SG_ 967 IPC_PowerRegenGaugeDisplay "IPC will display Power Regen Gauge based on user setting, and send Power Regen Gauge value by signal IPC_PowerRegenGaugeDisplay (%)";
CM_ SG_ 703 IPC_TripA "Set Trip A";
CM_ SG_ 703 IPC_AverageConsumptionTripA "Average Consumption of TripA";
CM_ SG_ 703 IPC_AverageSpeedTripA "Average Speed of TripA";
CM_ SG_ 703 IPC_VehicleFailureLevel "IPC VehicleFaultLevel";
CM_ SG_ 703 IPC_VehSpd "Current Displayed Longitudinal Vehicle Speed";
CM_ SG_ 1087 IPC_Year "Represents the current year.";
CM_ SG_ 1087 IPC_Month "Represents the current month.0, 13 to 15 = Invalid";
CM_ SG_ 1087 IPC_SelFCheckStatus "Power on selF check status";
CM_ SG_ 1087 IPC_Day "Represents the current dayInvalid value = 0";
CM_ SG_ 1087 IPC_Hour "Represents the current hour, 24 - 30 = not used";
CM_ SG_ 1087 IPC_Min "Represents the current minute. 60 - 63 = Invalid";
CM_ SG_ 1087 IPC_Sec "Represents the current second.60 - 63 = Invalid";
CM_ SG_ 524 CRC_IPC_0x20C "CRC_IPC_0x20C校验和";
CM_ SG_ 524 ALIVE_IPC_0x20C "ALIVE_IPC_0x20C心跳";
CM_ SG_ 524 IPC_ODO "odograph";
CM_ SG_ 677 CRC_IPC_0x2A5 "CRC_IPC_0x2A5校验和";
CM_ SG_ 677 ALIVE_IPC_0x2A5 "ALIVE_IPC_0x2A5心跳";
CM_ SG_ 677 IPC_ChargeScheduleSet "Request  enable/disable Charging Scheduling";
CM_ SG_ 677 IPC_ChargingRequest "IPC charging requestIPC充电请求";
CM_ SG_ 677 IPC_ChrSOCLitCtr "SOC charge limit controlSOC充电限制控制";
CM_ SG_ 676 CRC_IPC_0x2A4 "CRC_IPC_0x2A4校验和";
CM_ SG_ 676 ALIVE_IPC_0x2A4 "ALIVE_IPC_0x2A4心跳";
CM_ SG_ 676 IPC_EnergyRecSet "Energy recovery state能量回收状态";
CM_ SG_ 676 IPC_HSA_Set "Hill assist function  control 坡道辅助控制";
CM_ SG_ 676 IPC_DriveModeSet "Drive mode command  驾驶模式指令";
CM_ SG_ 676 IPC_VCU_CreepDisable_Stt "Request for VCU to disable creep funtion";
CM_ SG_ 676 IPC_DriveLockSpeedCtl "Driving lock speed control  行车落锁速度控制";
CM_ SG_ 1015 MFS_RightControl "Right Control";
CM_ SG_ 1015 MFS_LeftControl "Left Control";
CM_ SG_ 1015 MFS_DownControl "Down Control";
CM_ SG_ 1015 MFS_UpControl "Up Control";
CM_ SG_ 1015 MFS_Failure "MFS failure";
CM_ SG_ 1015 MFS_VOL_D "loudspeaker volume decrease";
CM_ SG_ 1015 MFS_VOL_U "loudspeaker volume increase";
CM_ SG_ 1015 MFS_OK_Control "OK Control";
CM_ SG_ 264 Checksum_0x108 "Check sum";
CM_ SG_ 264 Rolling_Counter_0x108 "Rolling Counter";
CM_ SG_ 264 SS_DriveModeReq_reserved "The drive mode request";
CM_ SG_ 264 SS_TargetGearReq "Target gear request";
CM_ SG_ 264 SS_Fault "Fault statue";
CM_ SG_ 264 FR_Wipercontrol_switch "Front Wiper control switch";
CM_ SG_ 264 Front_Wash "Front Wash Status";
CM_ SG_ 264 SS_FogLight_reserved "status of fog light";
CM_ SG_ 264 RR_Wiper "Rear wiper";
CM_ SG_ 264 SS_lane_change_lampSts "lane change light output Status";
CM_ SG_ 264 SS_Overtaking_lamp "Overtaking lamp output Status";
CM_ SG_ 264 SS_TurnIndicatorSts "Turn light output  Status";
CM_ SG_ 264 SS_PosLmpSts "Position light output Status";
CM_ SG_ 264 SS_LowBeamSts "Low beam output  Status";
CM_ SG_ 264 SS_HighBeamSts "High beam output Status";
CM_ SG_ 264 SS_HardNumLow "Hard Number Low";
CM_ SG_ 264 SS_HardNumHigh "Hard Number High";
CM_ SG_ 264 SS_SoftNumLow "Soft Number Low";
CM_ SG_ 264 SS_SoftNumHigh "Soft Number High";
CM_ SG_ 1236 BCM_FrontLeftDoorAjarStatus "Signal from BCM to indicate the ajar/close status of driver doorBCM信号提示任意左前（驾驶员）车门开启／关闭状态";
CM_ SG_ 1236 BCM_FrontRightDoorAjarStatus "Signal from BCM to indicate the ajar/close status of passenger doorBCM信号提示右前车门开启／关闭状态";
CM_ SG_ 1236 BCM_RightDoorLockStatusDrv "Right Driver Door Lock Status右前门锁状态";
CM_ SG_ 1236 BCM_LeftDoorLockStatusDrv "Left Driver Door Lock Status左前门锁状态";
CM_ SG_ 1236 BCM_ATWS_St "BCM Anti thelf warning status防盗报警状态";
CM_ SG_ 1236 BCM_STAT_DoorSpeedLock "Status feedback from BCM for Setting Door speed lock modeBCM状态反馈，用于设置门锁模式";
CM_ SG_ 262 CRC_BCM_0x106 "CRC_BCM_0x106校验和";
CM_ SG_ 262 ALIVE_BCM_0x106 "ALIVE_BCM_0x106循环计数";
CM_ SG_ 262 BCM_TurnIndicatorSts "Turn light output  Status转向灯输出状态";
CM_ SG_ 262 BCM_PosLmpSts "Position light output Status位置灯输出状态";
CM_ SG_ 262 BCM_LowBeamSts "Low beam output  Status近光灯输出状态";
CM_ SG_ 262 BCM_HighBeamSts "High beam output Status远光灯输出状态";
CM_ SG_ 262 BCM_BrakeLightSts "Brake Light output Status制动灯输出状态";
CM_ SG_ 262 BCM_ReverseLightSts "Reverse light output Status倒车灯输出状态";
CM_ SG_ 262 BCM_STAT_LightActivation "Status of light灯光状态";
CM_ SG_ 262 BCM_Fr_domelampSts "Dimming dome lamp Front Status前调光顶灯状态";
CM_ SG_ 262 BCM_LicensePlateLightSts "License plate light output牌照灯输出状态";
CM_ SG_ 262 BCM_STAT_InteriorLight "status of backlight illumination背光照明状态";
CM_ SG_ 262 BCM_STAT_SwLightBrightness "Determine the switch brightness确定开关光亮亮度";
CM_ SG_ 513 CRC_BCM_0x201 "CRC_BCM_0x201校验和";
CM_ SG_ 513 ALIVE_BCM_0x201 "ALIVE_BCM_0x201循环计数";
CM_ SG_ 513 BCM_LV_topupReq "LV_topupReq低压补电请求";
CM_ SG_ 513 BCM_BatteryVoltage "Input Voltage低压电池输入电压";
CM_ SG_ 513 BCM_Key_CheckSts "Key status Check钥匙状态检测";
CM_ SG_ 513 BCM_Press_BrkPedal_Alert "Please step on the brake pedal to remind请踩制动踏板提醒";
CM_ SG_ 513 BCM_EmergencyStop "Emergency power-off紧急下电（熄火）";
CM_ SG_ 513 BCM_IGN1RelayOutputSts "IGN1Relays output status";
CM_ SG_ 513 BCM_ACCRelayOutputSts "ACCRelays output status";
CM_ SG_ 513 BCM_FLWIN_Postion_Reserved "FL window postion左前窗位置";
CM_ SG_ 513 BCM_KEY_MatchSts "Match status with Key";
CM_ SG_ 513 BCM_FRWIN_Postion_Reserved "FR window postion右前窗位置";
CM_ SG_ 513 BCM_BCMFaultCode "BCM fault codeBCM故障码";
CM_ SG_ 513 BCM_PowerMode "BCM Power Distribution StatusBCM电源状态";
CM_ SG_ 513 BCM_BrakeSwSts "Break switch Status刹车开关状态";
CM_ SG_ 513 BCM_VehicleFailureLevel "BCM Vehicle failure levelBCM整车故障等级";
CM_ SG_ 513 BCM_Anti_theftAlarmSetSts "Anti_thef tAlarm Set Status防盗警报设置状态";
CM_ SG_ 513 BCM_FMH_SetSts "Follow me home Set Sts伴我回家设置状态";
CM_ SG_ 513 BCM_IGN1RelayFaultSts "IGN1Relays Fault Status";
CM_ SG_ 513 BCM_ACCRelayFaultSts "ACCRelays Fault Status";
CM_ SG_ 201 CRC_EDS_0xC9 "Check校验";
CM_ SG_ 201 ALIVE_EDS_0xC9 "RollingCounter循环计数";
CM_ SG_ 201 EDS_VCU_CtrMode "EDS control modeEDS控制模式";
CM_ SG_ 201 EDS_MotorSpdVD "Motor speed eFFectiveness 电机转速有效性";
CM_ SG_ 201 EDS_MotorTqVD "Motor torque eFFectiveness电机扭矩有效性";
CM_ SG_ 201 EDS_MotorTq "Motor torque  电机扭矩";
CM_ SG_ 201 EDS_MotorSpd "Motor speed   电机转速";
CM_ SG_ 201 EDS_HSA_Sts "Hill assist active status  坡道辅助激活状态";
CM_ SG_ 201 EDS_DriveSTS "EDS Drive StateEDS    EDS驱动状态";
CM_ SG_ 201 EDS_StsMode "EDS operating modeEDS工作模式";
CM_ SG_ 201 EDS_VehicleFailureLevel "EDS Vehicle Failure Level";
CM_ SG_ 201 EDS_HSA_Fault "HSA fault status 坡道辅助故障状态";
CM_ SG_ 871 CRC_EDS_0x367 "CheckSum校验和";
CM_ SG_ 871 ALIVE_EDS_0x367 "RollingCounter循环计数";
CM_ SG_ 871 EDS_IGBTTemp "IGBT temperature";
CM_ SG_ 871 EDS_Motor_statorTemp "Motor stator temperature";
CM_ SG_ 871 EDS_EDSTemp "EDS temperatureEDS温度";
CM_ SG_ 871 EDS_MotorTemp "Motor temperature 电机温度";
BA_DEF_ BO_  "DiagRequest" ENUM  "No","Yes";
BA_DEF_ BO_  "DiagResponse" ENUM  "No","Yes";
BA_DEF_ BO_  "GenMsgCycleTime" INT 0 65535;
BA_DEF_ BO_  "GenMsgCycleTimeFast" INT 0 65535;
BA_DEF_ BO_  "GenMsgDelayTime" INT 0 65535;
BA_DEF_ BO_  "GenMsgILSupport" ENUM  "No","Yes";
BA_DEF_ BO_  "GenMsgNrOfRepetition" INT 0 65535;
BA_DEF_ BO_  "GenMsgSendType" ENUM  "Cycle","Event","IfActive","CE","CA";
BA_DEF_ BO_  "NmAsrMessage" ENUM  "No","Yes";
BA_DEF_ BO_  "NmMessage" ENUM  "No","Yes";
BA_DEF_ SG_  "GenSigSendType" ENUM  "Cycle","OnWrite","OnWriteWithRepetition","OnChange","OnChangeWithRepetition","IfActive","IfActiveWithRepetition";
BA_DEF_ SG_  "GenSigStartValue" INT 0 2147483647;
BA_DEF_ SG_  "GenSigInvalidValue" INT 0 2147483647;
BA_DEF_ SG_  "GenSigInactiveValue" INT 0 2147483647;
BA_DEF_ BU_  "ILUsed" ENUM  "No","Yes";
BA_DEF_ BU_  "NmAsrCanMsgReducedTime" INT 320 640;
BA_DEF_ BU_  "NmAsrNode" ENUM  "No","Yes";
BA_DEF_  "Baudrate" INT 0 1000000;
BA_DEF_  "BusType" STRING ;
BA_DEF_  "Manufacturer" STRING ;
BA_DEF_  "NmAsrBaseAddress" HEX 0 2047;
BA_DEF_  "NmAsrCanMsgCycleTime" INT 0 65535;
BA_DEF_  "NmAsrMessageCount" INT 1 256;
BA_DEF_  "NmAsrRepeatMessageTime" INT 0 65535;
BA_DEF_  "NmAsrTimeoutTime" INT 0 65535;
BA_DEF_  "NmAsrWaitBusSleepTime" INT 0 65535;
BA_DEF_  "NmType" STRING ;
BA_DEF_DEF_  "DiagRequest" "No";
BA_DEF_DEF_  "DiagResponse" "No";
BA_DEF_DEF_  "GenMsgCycleTime" 0;
BA_DEF_DEF_  "GenMsgCycleTimeFast" 0;
BA_DEF_DEF_  "GenMsgDelayTime" 0;
BA_DEF_DEF_  "GenMsgILSupport" "Yes";
BA_DEF_DEF_  "GenMsgNrOfRepetition" 0;
BA_DEF_DEF_  "GenMsgSendType" "";
BA_DEF_DEF_  "NmAsrMessage" "No";
BA_DEF_DEF_  "NmMessage" "No";
BA_DEF_DEF_  "GenSigSendType" "";
BA_DEF_DEF_  "GenSigStartValue" 0;
BA_DEF_DEF_  "GenSigInvalidValue" 0;
BA_DEF_DEF_  "GenSigInactiveValue" 0;
BA_DEF_DEF_  "ILUsed" "Yes";
BA_DEF_DEF_  "NmAsrCanMsgReducedTime" 320;
BA_DEF_DEF_  "NmAsrNode" "No";
BA_DEF_DEF_  "Baudrate" 500000;
BA_DEF_DEF_  "BusType" "CAN";
BA_DEF_DEF_  "Manufacturer" "Launch";
BA_DEF_DEF_  "NmAsrBaseAddress" 1280;
BA_DEF_DEF_  "NmAsrCanMsgCycleTime" 640;
BA_DEF_DEF_  "NmAsrMessageCount" 128;
BA_DEF_DEF_  "NmAsrRepeatMessageTime" 3200;
BA_DEF_DEF_  "NmAsrTimeoutTime" 2000;
BA_DEF_DEF_  "NmAsrWaitBusSleepTime" 1500;
BA_DEF_DEF_  "NmType" "NmAsr";
BA_ "NmAsrNode" BU_ VCU 1;
BA_ "NmAsrNode" BU_ BCM 1;
BA_ "NmAsrNode" BU_ SS 1;
BA_ "NmAsrNode" BU_ IPC 1;
BA_ "GenMsgCycleTime" BO_ 133 20;
BA_ "GenMsgSendType" BO_ 133 0;
BA_ "GenMsgCycleTime" BO_ 897 200;
BA_ "GenMsgSendType" BO_ 897 0;
BA_ "GenMsgCycleTime" BO_ 1160 1000;
BA_ "GenMsgSendType" BO_ 1160 0;
BA_ "GenMsgCycleTime" BO_ 281 20;
BA_ "GenMsgSendType" BO_ 281 0;
BA_ "GenMsgCycleTime" BO_ 280 10;
BA_ "GenMsgSendType" BO_ 280 0;
BA_ "GenMsgCycleTime" BO_ 275 10;
BA_ "GenMsgSendType" BO_ 275 0;
BA_ "GenMsgCycleTime" BO_ 274 10;
BA_ "GenMsgSendType" BO_ 274 0;
BA_ "GenMsgCycleTime" BO_ 1145 100;
BA_ "GenMsgSendType" BO_ 1145 0;
BA_ "GenMsgCycleTime" BO_ 1221 20;
BA_ "GenMsgSendType" BO_ 1221 0;
BA_ "GenMsgCycleTime" BO_ 905 100;
BA_ "GenMsgSendType" BO_ 905 0;
BA_ "GenMsgCycleTime" BO_ 341 10;
BA_ "GenMsgSendType" BO_ 341 0;
BA_ "GenMsgCycleTime" BO_ 288 100;
BA_ "GenMsgSendType" BO_ 288 0;
BA_ "GenMsgCycleTime" BO_ 291 10;
BA_ "GenMsgSendType" BO_ 291 0;
BA_ "GenMsgCycleTime" BO_ 525 100;
BA_ "GenMsgSendType" BO_ 525 0;
BA_ "GenMsgCycleTime" BO_ 769 200;
BA_ "GenMsgSendType" BO_ 769 0;
BA_ "GenMsgCycleTime" BO_ 896 1000;
BA_ "GenMsgSendType" BO_ 896 0;
BA_ "GenMsgCycleTime" BO_ 1074 100;
BA_ "GenMsgSendType" BO_ 1074 0;
BA_ "GenMsgCycleTime" BO_ 1020 500;
BA_ "GenMsgSendType" BO_ 1020 0;
BA_ "GenMsgCycleTime" BO_ 967 100;
BA_ "GenMsgCycleTimeFast" BO_ 967 50;
BA_ "GenMsgDelayTime" BO_ 967 30;
BA_ "GenMsgNrOfRepetition" BO_ 967 5;
BA_ "GenMsgSendType" BO_ 967 0;
BA_ "GenMsgCycleTime" BO_ 703 50;
BA_ "GenMsgSendType" BO_ 703 0;
BA_ "GenMsgCycleTime" BO_ 1087 1000;
BA_ "GenMsgSendType" BO_ 1087 0;
BA_ "GenMsgCycleTime" BO_ 524 100;
BA_ "GenMsgSendType" BO_ 524 0;
BA_ "GenMsgCycleTime" BO_ 677 200;
BA_ "GenMsgSendType" BO_ 677 0;
BA_ "GenMsgCycleTime" BO_ 676 100;
BA_ "GenMsgSendType" BO_ 676 0;
BA_ "GenMsgCycleTime" BO_ 770 200;
BA_ "GenMsgSendType" BO_ 770 0;
BA_ "GenMsgCycleTime" BO_ 1015 100;
BA_ "GenMsgCycleTimeFast" BO_ 1015 50;
BA_ "GenMsgNrOfRepetition" BO_ 1015 5;
BA_ "GenMsgSendType" BO_ 1015 0;
BA_ "GenMsgCycleTime" BO_ 264 50;
BA_ "GenMsgSendType" BO_ 264 0;
BA_ "GenMsgCycleTime" BO_ 1236 150;
BA_ "GenMsgSendType" BO_ 1236 0;
BA_ "GenMsgCycleTime" BO_ 262 20;
BA_ "GenMsgSendType" BO_ 262 0;
BA_ "GenMsgCycleTime" BO_ 513 100;
BA_ "GenMsgSendType" BO_ 513 0;
BA_ "GenMsgCycleTime" BO_ 201 10;
BA_ "GenMsgSendType" BO_ 201 0;
BA_ "GenMsgCycleTime" BO_ 871 500;
BA_ "GenMsgSendType" BO_ 871 0;
BA_ "GenSigStartValue" SG_ 133 Checksum_0x85 255;
BA_ "GenSigSendType" SG_ 133 Checksum_0x85 0;
BA_ "GenSigInvalidValue" SG_ 133 Rolling_Counter_0x85 15;
BA_ "GenSigSendType" SG_ 133 Rolling_Counter_0x85 0;
BA_ "GenSigInvalidValue" SG_ 133 ACU_Crash_Sts 3;
BA_ "GenSigSendType" SG_ 133 ACU_Crash_Sts 0;
BA_ "GenSigInvalidValue" SG_ 133 ACU_Airbag_Deployment_Status 3;
BA_ "GenSigSendType" SG_ 133 ACU_Airbag_Deployment_Status 0;
BA_ "GenSigStartValue" SG_ 897 Checksum_0x381 255;
BA_ "GenSigSendType" SG_ 897 Checksum_0x381 0;
BA_ "GenSigInvalidValue" SG_ 897 Rolling_Counter_0x381 15;
BA_ "GenSigSendType" SG_ 897 Rolling_Counter_0x381 0;
BA_ "GenSigStartValue" SG_ 897 ACU_Seat_Occupancy_Passenger 2;
BA_ "GenSigSendType" SG_ 897 ACU_Seat_Occupancy_Passenger 0;
BA_ "GenSigSendType" SG_ 897 ACU_Seat_Belt_Status_Passenger 0;
BA_ "GenSigSendType" SG_ 897 ACU_Seat_Belt_Status_Driver 0;
BA_ "GenSigStartValue" SG_ 1160 CRC_ACU_0x488 255;
BA_ "GenSigSendType" SG_ 1160 CRC_ACU_0x488 0;
BA_ "GenSigInvalidValue" SG_ 1160 Alive_ACU_0x488 15;
BA_ "GenSigSendType" SG_ 1160 Alive_ACU_0x488 0;
BA_ "GenSigStartValue" SG_ 1160 ACU_Malfunction 1;
BA_ "GenSigSendType" SG_ 1160 ACU_Malfunction 0;
BA_ "GenSigSendType" SG_ 1160 ACU_Pre_Drive_Check 0;
BA_ "GenSigStartValue" SG_ 1160 ACU_in_Plant_Mode 1;
BA_ "GenSigSendType" SG_ 1160 ACU_in_Plant_Mode 0;
BA_ "GenSigSendType" SG_ 1160 ACU_PAB_Suppression 0;
BA_ "GenSigSendType" SG_ 1160 ACU_Airbag_Disabled 0;
BA_ "GenSigSendType" SG_ 1160 ACU_Development_Calibration 0;
BA_ "GenSigStartValue" SG_ 1160 ACU_In_Disposal_Mode 1;
BA_ "GenSigSendType" SG_ 1160 ACU_In_Disposal_Mode 0;
BA_ "GenSigSendType" SG_ 1160 ACU_VehicleFailureLevel 0;
BA_ "GenSigStartValue" SG_ 1160 ACU_Seatbelt_Reminder_Request 1;
BA_ "GenSigSendType" SG_ 1160 ACU_Seatbelt_Reminder_Request 0;
BA_ "GenSigStartValue" SG_ 1160 ACU_SBR_Chime_Req 1;
BA_ "GenSigSendType" SG_ 1160 ACU_SBR_Chime_Req 0;
BA_ "GenSigStartValue" SG_ 1160 ACU_SBR_Blinking_Req 1;
BA_ "GenSigSendType" SG_ 1160 ACU_SBR_Blinking_Req 0;
BA_ "GenSigStartValue" SG_ 281 CRC_ABS_0x119 255;
BA_ "GenSigSendType" SG_ 281 CRC_ABS_0x119 0;
BA_ "GenSigInvalidValue" SG_ 281 ALIVE_ABS_0x119 15;
BA_ "GenSigSendType" SG_ 281 ALIVE_ABS_0x119 0;
BA_ "GenSigStartValue" SG_ 281 ABS_DTCDecReqTorque 2000;
BA_ "GenSigSendType" SG_ 281 ABS_DTCDecReqTorque 0;
BA_ "GenSigSendType" SG_ 281 ABS_DTCActiveSts 0;
BA_ "GenSigSendType" SG_ 281 ABS_DTCSystemSts 0;
BA_ "GenSigSendType" SG_ 281 ABS_DTCDecReqTorqueV 0;
BA_ "GenSigSendType" SG_ 281 ABS_ASRDecReqTorque 0;
BA_ "GenSigSendType" SG_ 281 ABS_ASRSwState 0;
BA_ "GenSigSendType" SG_ 281 ABS_ASRActiveSts 0;
BA_ "GenSigSendType" SG_ 281 ABS_ASRSystemSts 0;
BA_ "GenSigSendType" SG_ 281 ABS_ASRDecReqTorqueV 0;
BA_ "GenSigSendType" SG_ 281 ABS_MasterCylinderPressure 0;
BA_ "GenSigStartValue" SG_ 280 CRC_ABS_0x118 255;
BA_ "GenSigSendType" SG_ 280 CRC_ABS_0x118 0;
BA_ "GenSigInvalidValue" SG_ 280 ALIVE_ABS_0x118 15;
BA_ "GenSigSendType" SG_ 280 ALIVE_ABS_0x118 0;
BA_ "GenSigStartValue" SG_ 280 ABS_HazardLightsOnReq 1;
BA_ "GenSigSendType" SG_ 280 ABS_HazardLightsOnReq 0;
BA_ "GenSigStartValue" SG_ 280 ABS_BrakeLightsOnReq 1;
BA_ "GenSigSendType" SG_ 280 ABS_BrakeLightsOnReq 0;
BA_ "GenSigSendType" SG_ 280 ABS_TcsFlgFlt 0;
BA_ "GenSigSendType" SG_ 280 ABS_TCS_Active 0;
BA_ "GenSigSendType" SG_ 280 ABS_ABSActive 0;
BA_ "GenSigSendType" SG_ 280 ABS_EBDFault 0;
BA_ "GenSigSendType" SG_ 280 ABS_ABSFault 0;
BA_ "GenSigSendType" SG_ 280 ABS_TCS_OFF_State 0;
BA_ "GenSigSendType" SG_ 280 ABS_VehicleFailureLevel 0;
BA_ "GenSigSendType" SG_ 280 ABS_RBSInhibitFlag 0;
BA_ "GenSigSendType" SG_ 280 ABS_EBDActive 0;
BA_ "GenSigInvalidValue" SG_ 280 ABS_VehicleSpeed 32767;
BA_ "GenSigSendType" SG_ 280 ABS_VehicleSpeed 0;
BA_ "GenSigSendType" SG_ 280 ABS_VehicleSpeedV 0;
BA_ "GenSigStartValue" SG_ 275 CRC_ABS_0x113 255;
BA_ "GenSigSendType" SG_ 275 CRC_ABS_0x113 0;
BA_ "GenSigInvalidValue" SG_ 275 ALIVE_ABS_0x113 15;
BA_ "GenSigSendType" SG_ 275 ALIVE_ABS_0x113 0;
BA_ "GenSigSendType" SG_ 275 ABS_WheelSpeedFL 0;
BA_ "GenSigSendType" SG_ 275 ABS_PulseCounterFLV 0;
BA_ "GenSigSendType" SG_ 275 ABS_WheelSpeedFLV 0;
BA_ "GenSigSendType" SG_ 275 ABS_WheelSpeedFR 0;
BA_ "GenSigSendType" SG_ 275 ABS_PulseCounterFRV 0;
BA_ "GenSigSendType" SG_ 275 ABS_WheelSpeedFRV 0;
BA_ "GenSigSendType" SG_ 275 ABS_PulseCounterFL 0;
BA_ "GenSigSendType" SG_ 275 ABS_PulseCounterFR 0;
BA_ "GenSigStartValue" SG_ 274 CRC_ABS_0x112 255;
BA_ "GenSigSendType" SG_ 274 CRC_ABS_0x112 0;
BA_ "GenSigInvalidValue" SG_ 274 ALIVE_ABS_0x112 15;
BA_ "GenSigSendType" SG_ 274 ALIVE_ABS_0x112 0;
BA_ "GenSigSendType" SG_ 274 ABS_WheelSpeedRL 0;
BA_ "GenSigSendType" SG_ 274 ABS_PulseCounterRLV 0;
BA_ "GenSigSendType" SG_ 274 ABS_WheelSpeedRLV 0;
BA_ "GenSigSendType" SG_ 274 ABS_WheelSpeedRR 0;
BA_ "GenSigSendType" SG_ 274 ABS_PulseCounterRRV 0;
BA_ "GenSigSendType" SG_ 274 ABS_WheelSpeedRRV 0;
BA_ "GenSigSendType" SG_ 274 ABS_PulseCounterRL 0;
BA_ "GenSigSendType" SG_ 274 ABS_PulseCounterRR 0;
BA_ "GenSigSendType" SG_ 1145 VCU_FaultCode 0;
BA_ "GenSigSendType" SG_ 1145 VCU_VehicleFailureLevel 0;
BA_ "GenSigSendType" SG_ 1145 VCU_EDSCAN_ERR 0;
BA_ "GenSigSendType" SG_ 1145 VCU_BmsCAN_ERR 0;
BA_ "GenSigSendType" SG_ 1145 VCU_DcdcCAN_ERR 0;
BA_ "GenSigSendType" SG_ 1145 VCU_AbsCAN_ERR 0;
BA_ "GenSigSendType" SG_ 1145 VCU_ACUCAN_ERR 0;
BA_ "GenSigSendType" SG_ 1145 VCU_BcmCAN_ERR_reserved 0;
BA_ "GenSigSendType" SG_ 1145 VCU_BrakeSys_Err 0;
BA_ "GenSigSendType" SG_ 1145 VCU_AccPed_ERR 0;
BA_ "GenSigSendType" SG_ 1145 VCU_Shift_ERR 0;
BA_ "GenSigSendType" SG_ 1145 VCU_EPSCAN_ERR 0;
BA_ "GenSigSendType" SG_ 1145 VCU_EvccCAN_ERR 0;
BA_ "GenSigSendType" SG_ 1145 VCU_FlgHVIL_ERR 0;
BA_ "GenSigSendType" SG_ 1145 VCU_ObcCAN_ERR 0;
BA_ "GenSigSendType" SG_ 1145 VCU_SSCAN_ERR 0;
BA_ "GenSigSendType" SG_ 1145 VCU_EacCAN_ERR 0;
BA_ "GenSigSendType" SG_ 1145 VCU_AccPedalOutRange 0;
BA_ "GenSigStartValue" SG_ 1221 CRC_VCU_0x4C5 255;
BA_ "GenSigSendType" SG_ 1221 CRC_VCU_0x4C5 0;
BA_ "GenSigInvalidValue" SG_ 1221 ALIVE_VCU_0x4C5 15;
BA_ "GenSigSendType" SG_ 1221 ALIVE_VCU_0x4C5 0;
BA_ "GenSigSendType" SG_ 1221 VCU_CreepDisable_stt 0;
BA_ "GenSigSendType" SG_ 1221 VCU_RDCSts 0;
BA_ "GenSigSendType" SG_ 1221 VCU_RBCSts 0;
BA_ "GenSigSendType" SG_ 1221 VCU_BrkPedalSWSts 0;
BA_ "GenSigSendType" SG_ 1221 Brakefluid_levelSts 0;
BA_ "GenSigSendType" SG_ 1221 VCU_HandBrakeSts 0;
BA_ "GenSigSendType" SG_ 1221 VCU_RegenLevelfeed 0;
BA_ "GenSigSendType" SG_ 1221 VCU_PowerLimit 0;
BA_ "GenSigSendType" SG_ 1221 VCU_AccPedaPosValid 0;
BA_ "GenSigSendType" SG_ 1221 VCU_AccPedaPos 0;
BA_ "GenSigSendType" SG_ 1221 VCU_VehicleHVStatus 0;
BA_ "GenSigSendType" SG_ 1221 VCU_VacuumPresWrn 0;
BA_ "GenSigSendType" SG_ 1221 VCU_VacuumSts 0;
BA_ "GenSigSendType" SG_ 1221 VCU_InstantPowerConsump 0;
BA_ "GenSigSendType" SG_ 1221 VCU_AveragePowerConsump 0;
BA_ "GenSigSendType" SG_ 1221 VCU_LowSOCWarning 0;
BA_ "GenSigSendType" SG_ 1221 VCU_TqReductionRqstResponse 0;
BA_ "GenSigSendType" SG_ 1221 VCU_DrvModeSts 0;
BA_ "GenSigSendType" SG_ 905 VCU_VacuumPumpEna 0;
BA_ "GenSigSendType" SG_ 905 VCU_Ambient_Pres 0;
BA_ "GenSigStartValue" SG_ 905 VCU_Vacuum_Pres 150;
BA_ "GenSigSendType" SG_ 905 VCU_Vacuum_Pres 0;
BA_ "GenSigStartValue" SG_ 341 CRC_VCU_0x155 255;
BA_ "GenSigSendType" SG_ 341 CRC_VCU_0x155 0;
BA_ "GenSigInvalidValue" SG_ 341 ALIVE_VCU_0x155 15;
BA_ "GenSigSendType" SG_ 341 ALIVE_VCU_0x155 0;
BA_ "GenSigSendType" SG_ 341 VCU_VecChrgRqst 0;
BA_ "GenSigSendType" SG_ 341 VCU_Vechg_Status 0;
BA_ "GenSigSendType" SG_ 341 VCU_VecOptMod 0;
BA_ "GenSigSendType" SG_ 341 VCU_BMSHvPowOnRqst 0;
BA_ "GenSigStartValue" SG_ 341 VCU_DrTorqRqst 2044;
BA_ "GenSigSendType" SG_ 341 VCU_DrTorqRqst 0;
BA_ "GenSigSendType" SG_ 341 VCU_VecActGearStsV 0;
BA_ "GenSigSendType" SG_ 341 VCU_VecActGearSts 0;
BA_ "GenSigSendType" SG_ 341 VCU_LV_topupSts 0;
BA_ "GenSigInvalidValue" SG_ 341 VCU_DrTorqRqstV 1;
BA_ "GenSigSendType" SG_ 341 VCU_DrTorqRqstV 0;
BA_ "GenSigStartValue" SG_ 341 VCU_ABS_TrqReqOrLmt 20000;
BA_ "GenSigInvalidValue" SG_ 341 VCU_ABS_TrqReqOrLmt 65535;
BA_ "GenSigSendType" SG_ 341 VCU_ABS_TrqReqOrLmt 0;
BA_ "GenSigStartValue" SG_ 288 CRC_VCU_0x120 255;
BA_ "GenSigSendType" SG_ 288 CRC_VCU_0x120 0;
BA_ "GenSigInvalidValue" SG_ 288 ALIVE_VCU_0x120 15;
BA_ "GenSigSendType" SG_ 288 ALIVE_VCU_0x120 0;
BA_ "GenSigSendType" SG_ 288 VCU_RemainMileageVD 0;
BA_ "GenSigSendType" SG_ 288 VCU_RemainMileage 0;
BA_ "GenSigStartValue" SG_ 291 CRC_VCU_0x123 255;
BA_ "GenSigSendType" SG_ 291 CRC_VCU_0x123 0;
BA_ "GenSigInvalidValue" SG_ 291 ALIVE_VCU_0x123 15;
BA_ "GenSigSendType" SG_ 291 ALIVE_VCU_0x123 0;
BA_ "GenSigStartValue" SG_ 291 VCU_Drive_TargetTqMin 500;
BA_ "GenSigInvalidValue" SG_ 291 VCU_Drive_TargetTqMin 1023;
BA_ "GenSigSendType" SG_ 291 VCU_Drive_TargetTqMin 0;
BA_ "GenSigInvalidValue" SG_ 291 VCU_Drive_TargetTqMax 1023;
BA_ "GenSigSendType" SG_ 291 VCU_Drive_TargetTqMax 0;
BA_ "GenSigStartValue" SG_ 525 Checksum_0x20D 255;
BA_ "GenSigSendType" SG_ 525 Checksum_0x20D 0;
BA_ "GenSigInvalidValue" SG_ 525 Rolling_Counter_0x20D 15;
BA_ "GenSigSendType" SG_ 525 Rolling_Counter_0x20D 0;
BA_ "GenSigInvalidValue" SG_ 525 VCU_ODO 1048575;
BA_ "GenSigSendType" SG_ 525 VCU_ODO 0;
BA_ "GenSigSendType" SG_ 769 VOD_Block 0;
BA_ "GenSigSendType" SG_ 769 VOD_UpdateFlag 0;
BA_ "GenSigStartValue" SG_ 769 VOD_Byte1 255;
BA_ "GenSigSendType" SG_ 769 VOD_Byte1 0;
BA_ "GenSigStartValue" SG_ 769 VOD_Byte2 255;
BA_ "GenSigSendType" SG_ 769 VOD_Byte2 0;
BA_ "GenSigStartValue" SG_ 769 VOD_Byte3 255;
BA_ "GenSigSendType" SG_ 769 VOD_Byte3 0;
BA_ "GenSigStartValue" SG_ 769 VOD_Byte4 255;
BA_ "GenSigSendType" SG_ 769 VOD_Byte4 0;
BA_ "GenSigStartValue" SG_ 769 VOD_Byte5 255;
BA_ "GenSigSendType" SG_ 769 VOD_Byte5 0;
BA_ "GenSigStartValue" SG_ 769 VOD_Byte6 255;
BA_ "GenSigSendType" SG_ 769 VOD_Byte6 0;
BA_ "GenSigStartValue" SG_ 769 VOD_Byte7 255;
BA_ "GenSigSendType" SG_ 769 VOD_Byte7 0;
BA_ "GenSigSendType" SG_ 896 VIN_Byte1 0;
BA_ "GenSigSendType" SG_ 896 VIN_Byte2 0;
BA_ "GenSigSendType" SG_ 896 VIN_Byte3 0;
BA_ "GenSigSendType" SG_ 896 VIN_Byte4 0;
BA_ "GenSigSendType" SG_ 896 VIN_Byte5 0;
BA_ "GenSigSendType" SG_ 896 VIN_Byte6 0;
BA_ "GenSigSendType" SG_ 896 VIN_Byte7 0;
BA_ "GenSigStartValue" SG_ 1074 Checksum_0x432 255;
BA_ "GenSigSendType" SG_ 1074 Checksum_0x432 0;
BA_ "GenSigInvalidValue" SG_ 1074 Rolling_Counter_0x432 15;
BA_ "GenSigSendType" SG_ 1074 Rolling_Counter_0x432 0;
BA_ "GenSigSendType" SG_ 1074 IPC_FOTA_State 0;
BA_ "GenSigStartValue" SG_ 1020 CRC_VCU_0x3FC 255;
BA_ "GenSigSendType" SG_ 1020 CRC_VCU_0x3FC 0;
BA_ "GenSigInvalidValue" SG_ 1020 ALIV_VCU_0x3FC 15;
BA_ "GenSigSendType" SG_ 1020 ALIV_VCU_0x3FC 0;
BA_ "GenSigStartValue" SG_ 1020 VCU_FOTA_Error_Code 63;
BA_ "GenSigInvalidValue" SG_ 1020 VCU_FOTA_Error_Code 255;
BA_ "GenSigSendType" SG_ 1020 VCU_FOTA_Error_Code 0;
BA_ "GenSigSendType" SG_ 1020 VCU_FOTA_StateConfirm 0;
BA_ "GenSigSendType" SG_ 967 IPC_Wiper_Repair_Mode 2;
BA_ "GenSigStartValue" SG_ 967 IPC_St_Dimming 10;
BA_ "GenSigInvalidValue" SG_ 967 IPC_St_Dimming 15;
BA_ "GenSigSendType" SG_ 967 IPC_St_Dimming 2;
BA_ "GenSigInvalidValue" SG_ 967 IPC_SET_Volume 255;
BA_ "GenSigSendType" SG_ 967 IPC_SET_Volume 2;
BA_ "GenSigStartValue" SG_ 967 IPC_VehsSpd_Warn 12000;
BA_ "GenSigInvalidValue" SG_ 967 IPC_VehsSpd_Warn 32767;
BA_ "GenSigSendType" SG_ 967 IPC_VehsSpd_Warn 2;
BA_ "GenSigStartValue" SG_ 967 IPC_PowerRegenGaugeDisplay 100;
BA_ "GenSigInvalidValue" SG_ 967 IPC_PowerRegenGaugeDisplay 255;
BA_ "GenSigSendType" SG_ 967 IPC_PowerRegenGaugeDisplay 0;
BA_ "GenSigSendType" SG_ 703 IPC_TripA 0;
BA_ "GenSigSendType" SG_ 703 IPC_AverageConsumptionTripA 0;
BA_ "GenSigSendType" SG_ 703 IPC_AverageSpeedTripA 0;
BA_ "GenSigSendType" SG_ 703 IPC_VehicleFailureLevel 0;
BA_ "GenSigSendType" SG_ 703 IPC_VehSpd 0;
BA_ "GenSigInvalidValue" SG_ 1087 IPC_Year 255;
BA_ "GenSigSendType" SG_ 1087 IPC_Year 0;
BA_ "GenSigStartValue" SG_ 1087 IPC_Month 1;
BA_ "GenSigInvalidValue" SG_ 1087 IPC_Month 15;
BA_ "GenSigSendType" SG_ 1087 IPC_Month 0;
BA_ "GenSigSendType" SG_ 1087 IPC_SelFCheckStatus 0;
BA_ "GenSigStartValue" SG_ 1087 IPC_Day 1;
BA_ "GenSigInvalidValue" SG_ 1087 IPC_Day 31;
BA_ "GenSigSendType" SG_ 1087 IPC_Day 0;
BA_ "GenSigInvalidValue" SG_ 1087 IPC_Hour 31;
BA_ "GenSigSendType" SG_ 1087 IPC_Hour 0;
BA_ "GenSigInvalidValue" SG_ 1087 IPC_Min 63;
BA_ "GenSigSendType" SG_ 1087 IPC_Min 0;
BA_ "GenSigInvalidValue" SG_ 1087 IPC_Sec 63;
BA_ "GenSigSendType" SG_ 1087 IPC_Sec 0;
BA_ "GenSigStartValue" SG_ 524 CRC_IPC_0x20C 255;
BA_ "GenSigSendType" SG_ 524 CRC_IPC_0x20C 0;
BA_ "GenSigInvalidValue" SG_ 524 ALIVE_IPC_0x20C 15;
BA_ "GenSigSendType" SG_ 524 ALIVE_IPC_0x20C 0;
BA_ "GenSigStartValue" SG_ 524 IPC_ODO 1048575;
BA_ "GenSigSendType" SG_ 524 IPC_ODO 0;
BA_ "GenSigStartValue" SG_ 677 CRC_IPC_0x2A5 255;
BA_ "GenSigSendType" SG_ 677 CRC_IPC_0x2A5 0;
BA_ "GenSigInvalidValue" SG_ 677 ALIVE_IPC_0x2A5 15;
BA_ "GenSigSendType" SG_ 677 ALIVE_IPC_0x2A5 0;
BA_ "GenSigSendType" SG_ 677 IPC_ChargeScheduleSet 0;
BA_ "GenSigSendType" SG_ 677 IPC_ChargingRequest 0;
BA_ "GenSigStartValue" SG_ 677 IPC_ChrSOCLitCtr 1000;
BA_ "GenSigSendType" SG_ 677 IPC_ChrSOCLitCtr 0;
BA_ "GenSigStartValue" SG_ 676 CRC_IPC_0x2A4 255;
BA_ "GenSigSendType" SG_ 676 CRC_IPC_0x2A4 0;
BA_ "GenSigInvalidValue" SG_ 676 ALIVE_IPC_0x2A4 15;
BA_ "GenSigSendType" SG_ 676 ALIVE_IPC_0x2A4 0;
BA_ "GenSigSendType" SG_ 676 IPC_EnergyRecSet 0;
BA_ "GenSigSendType" SG_ 676 IPC_HSA_Set 0;
BA_ "GenSigSendType" SG_ 676 IPC_DriveModeSet 0;
BA_ "GenSigSendType" SG_ 676 IPC_VCU_CreepDisable_Stt 0;
BA_ "GenSigSendType" SG_ 676 IPC_DriveLockSpeedCtl 0;
BA_ "GenSigSendType" SG_ 770 IPC_VOD_Block 0;
BA_ "GenSigSendType" SG_ 770 IPC_VOD_UpdateFlag 0;
BA_ "GenSigStartValue" SG_ 770 IPC_VOD_Byte1 255;
BA_ "GenSigSendType" SG_ 770 IPC_VOD_Byte1 0;
BA_ "GenSigStartValue" SG_ 770 IPC_VOD_Byte2 255;
BA_ "GenSigSendType" SG_ 770 IPC_VOD_Byte2 0;
BA_ "GenSigStartValue" SG_ 770 IPC_VOD_Byte3 255;
BA_ "GenSigSendType" SG_ 770 IPC_VOD_Byte3 0;
BA_ "GenSigStartValue" SG_ 770 IPC_VOD_Byte4 255;
BA_ "GenSigSendType" SG_ 770 IPC_VOD_Byte4 0;
BA_ "GenSigStartValue" SG_ 770 IPC_VOD_Byte5 255;
BA_ "GenSigSendType" SG_ 770 IPC_VOD_Byte5 0;
BA_ "GenSigStartValue" SG_ 770 IPC_VOD_Byte6 255;
BA_ "GenSigSendType" SG_ 770 IPC_VOD_Byte6 0;
BA_ "GenSigStartValue" SG_ 770 IPC_VOD_Byte7 255;
BA_ "GenSigSendType" SG_ 770 IPC_VOD_Byte7 0;
BA_ "GenSigInvalidValue" SG_ 1015 MFS_RightControl 3;
BA_ "GenSigSendType" SG_ 1015 MFS_RightControl 4;
BA_ "GenSigInvalidValue" SG_ 1015 MFS_LeftControl 3;
BA_ "GenSigSendType" SG_ 1015 MFS_LeftControl 4;
BA_ "GenSigInvalidValue" SG_ 1015 MFS_DownControl 3;
BA_ "GenSigSendType" SG_ 1015 MFS_DownControl 4;
BA_ "GenSigInvalidValue" SG_ 1015 MFS_UpControl 3;
BA_ "GenSigSendType" SG_ 1015 MFS_UpControl 4;
BA_ "GenSigInvalidValue" SG_ 1015 MFS_Failure 3;
BA_ "GenSigSendType" SG_ 1015 MFS_Failure 4;
BA_ "GenSigInvalidValue" SG_ 1015 MFS_VOL_D 3;
BA_ "GenSigSendType" SG_ 1015 MFS_VOL_D 4;
BA_ "GenSigInvalidValue" SG_ 1015 MFS_VOL_U 3;
BA_ "GenSigSendType" SG_ 1015 MFS_VOL_U 4;
BA_ "GenSigInvalidValue" SG_ 1015 MFS_OK_Control 3;
BA_ "GenSigSendType" SG_ 1015 MFS_OK_Control 4;
BA_ "GenSigStartValue" SG_ 264 Checksum_0x108 255;
BA_ "GenSigSendType" SG_ 264 Checksum_0x108 0;
BA_ "GenSigInvalidValue" SG_ 264 Rolling_Counter_0x108 15;
BA_ "GenSigSendType" SG_ 264 Rolling_Counter_0x108 0;
BA_ "GenSigSendType" SG_ 264 SS_DriveModeReq_reserved 0;
BA_ "GenSigInvalidValue" SG_ 264 SS_TargetGearReq 4;
BA_ "GenSigSendType" SG_ 264 SS_TargetGearReq 0;
BA_ "GenSigSendType" SG_ 264 SS_Fault 0;
BA_ "GenSigSendType" SG_ 264 FR_Wipercontrol_switch 0;
BA_ "GenSigSendType" SG_ 264 Front_Wash 0;
BA_ "GenSigSendType" SG_ 264 SS_FogLight_reserved 0;
BA_ "GenSigSendType" SG_ 264 RR_Wiper 0;
BA_ "GenSigSendType" SG_ 264 SS_lane_change_lampSts 0;
BA_ "GenSigSendType" SG_ 264 SS_Overtaking_lamp 0;
BA_ "GenSigSendType" SG_ 264 SS_TurnIndicatorSts 0;
BA_ "GenSigSendType" SG_ 264 SS_PosLmpSts 0;
BA_ "GenSigSendType" SG_ 264 SS_LowBeamSts 0;
BA_ "GenSigSendType" SG_ 264 SS_HighBeamSts 0;
BA_ "GenSigStartValue" SG_ 264 SS_HardNumLow 15;
BA_ "GenSigSendType" SG_ 264 SS_HardNumLow 0;
BA_ "GenSigStartValue" SG_ 264 SS_HardNumHigh 15;
BA_ "GenSigSendType" SG_ 264 SS_HardNumHigh 0;
BA_ "GenSigStartValue" SG_ 264 SS_SoftNumLow 15;
BA_ "GenSigSendType" SG_ 264 SS_SoftNumLow 0;
BA_ "GenSigStartValue" SG_ 264 SS_SoftNumHigh 15;
BA_ "GenSigSendType" SG_ 264 SS_SoftNumHigh 0;
BA_ "GenSigSendType" SG_ 1236 BCM_FrontLeftDoorAjarStatus 0;
BA_ "GenSigSendType" SG_ 1236 BCM_FrontRightDoorAjarStatus 0;
BA_ "GenSigSendType" SG_ 1236 BCM_RightDoorLockStatusDrv 0;
BA_ "GenSigSendType" SG_ 1236 BCM_LeftDoorLockStatusDrv 0;
BA_ "GenSigSendType" SG_ 1236 BCM_ATWS_St 0;
BA_ "GenSigSendType" SG_ 1236 BCM_STAT_DoorSpeedLock 0;
BA_ "GenSigStartValue" SG_ 262 CRC_BCM_0x106 255;
BA_ "GenSigSendType" SG_ 262 CRC_BCM_0x106 0;
BA_ "GenSigInvalidValue" SG_ 262 ALIVE_BCM_0x106 15;
BA_ "GenSigSendType" SG_ 262 ALIVE_BCM_0x106 0;
BA_ "GenSigSendType" SG_ 262 BCM_TurnIndicatorSts 0;
BA_ "GenSigSendType" SG_ 262 BCM_PosLmpSts 0;
BA_ "GenSigSendType" SG_ 262 BCM_LowBeamSts 0;
BA_ "GenSigSendType" SG_ 262 BCM_HighBeamSts 0;
BA_ "GenSigSendType" SG_ 262 BCM_BrakeLightSts 0;
BA_ "GenSigSendType" SG_ 262 BCM_ReverseLightSts 0;
BA_ "GenSigStartValue" SG_ 262 BCM_STAT_LightActivation 7;
BA_ "GenSigSendType" SG_ 262 BCM_STAT_LightActivation 0;
BA_ "GenSigSendType" SG_ 262 BCM_Fr_domelampSts 0;
BA_ "GenSigSendType" SG_ 262 BCM_LicensePlateLightSts 0;
BA_ "GenSigStartValue" SG_ 262 BCM_STAT_InteriorLight 3;
BA_ "GenSigSendType" SG_ 262 BCM_STAT_InteriorLight 0;
BA_ "GenSigStartValue" SG_ 262 BCM_STAT_SwLightBrightness 80;
BA_ "GenSigSendType" SG_ 262 BCM_STAT_SwLightBrightness 0;
BA_ "GenSigStartValue" SG_ 513 CRC_BCM_0x201 255;
BA_ "GenSigSendType" SG_ 513 CRC_BCM_0x201 0;
BA_ "GenSigInvalidValue" SG_ 513 ALIVE_BCM_0x201 15;
BA_ "GenSigSendType" SG_ 513 ALIVE_BCM_0x201 0;
BA_ "GenSigSendType" SG_ 513 BCM_LV_topupReq 0;
BA_ "GenSigSendType" SG_ 513 BCM_BatteryVoltage 0;
BA_ "GenSigSendType" SG_ 513 BCM_Key_CheckSts 0;
BA_ "GenSigSendType" SG_ 513 BCM_Press_BrkPedal_Alert 0;
BA_ "GenSigSendType" SG_ 513 BCM_EmergencyStop 0;
BA_ "GenSigSendType" SG_ 513 BCM_IGN1RelayOutputSts 0;
BA_ "GenSigSendType" SG_ 513 BCM_ACCRelayOutputSts 0;
BA_ "GenSigSendType" SG_ 513 BCM_FLWIN_Postion_Reserved 0;
BA_ "GenSigSendType" SG_ 513 BCM_KEY_MatchSts 0;
BA_ "GenSigSendType" SG_ 513 BCM_FRWIN_Postion_Reserved 0;
BA_ "GenSigSendType" SG_ 513 BCM_BCMFaultCode 0;
BA_ "GenSigSendType" SG_ 513 BCM_PowerMode 0;
BA_ "GenSigSendType" SG_ 513 BCM_BrakeSwSts 0;
BA_ "GenSigSendType" SG_ 513 BCM_VehicleFailureLevel 0;
BA_ "GenSigStartValue" SG_ 513 BCM_Anti_theftAlarmSetSts 2;
BA_ "GenSigSendType" SG_ 513 BCM_Anti_theftAlarmSetSts 0;
BA_ "GenSigSendType" SG_ 513 BCM_FMH_SetSts 0;
BA_ "GenSigSendType" SG_ 513 BCM_IGN1RelayFaultSts 0;
BA_ "GenSigSendType" SG_ 513 BCM_ACCRelayFaultSts 0;
BA_ "GenSigStartValue" SG_ 201 CRC_EDS_0xC9 255;
BA_ "GenSigSendType" SG_ 201 CRC_EDS_0xC9 0;
BA_ "GenSigInvalidValue" SG_ 201 ALIVE_EDS_0xC9 15;
BA_ "GenSigSendType" SG_ 201 ALIVE_EDS_0xC9 0;
BA_ "GenSigSendType" SG_ 201 EDS_VCU_CtrMode 0;
BA_ "GenSigInvalidValue" SG_ 201 EDS_MotorSpdVD 1;
BA_ "GenSigSendType" SG_ 201 EDS_MotorSpdVD 0;
BA_ "GenSigInvalidValue" SG_ 201 EDS_MotorTqVD 1;
BA_ "GenSigSendType" SG_ 201 EDS_MotorTqVD 0;
BA_ "GenSigStartValue" SG_ 201 EDS_MotorTq 12000;
BA_ "GenSigSendType" SG_ 201 EDS_MotorTq 0;
BA_ "GenSigStartValue" SG_ 201 EDS_MotorSpd 20000;
BA_ "GenSigSendType" SG_ 201 EDS_MotorSpd 0;
BA_ "GenSigSendType" SG_ 201 EDS_HSA_Sts 0;
BA_ "GenSigSendType" SG_ 201 EDS_DriveSTS 0;
BA_ "GenSigSendType" SG_ 201 EDS_StsMode 0;
BA_ "GenSigSendType" SG_ 201 EDS_VehicleFailureLevel 0;
BA_ "GenSigSendType" SG_ 201 EDS_HSA_Fault 0;
BA_ "GenSigStartValue" SG_ 871 CRC_EDS_0x367 255;
BA_ "GenSigSendType" SG_ 871 CRC_EDS_0x367 0;
BA_ "GenSigInvalidValue" SG_ 871 ALIVE_EDS_0x367 15;
BA_ "GenSigSendType" SG_ 871 ALIVE_EDS_0x367 0;
BA_ "GenSigStartValue" SG_ 871 EDS_IGBTTemp 40;
BA_ "GenSigSendType" SG_ 871 EDS_IGBTTemp 0;
BA_ "GenSigStartValue" SG_ 871 EDS_Motor_statorTemp 40;
BA_ "GenSigSendType" SG_ 871 EDS_Motor_statorTemp 0;
BA_ "GenSigStartValue" SG_ 871 EDS_EDSTemp 40;
BA_ "GenSigSendType" SG_ 871 EDS_EDSTemp 0;
BA_ "GenSigStartValue" SG_ 871 EDS_MotorTemp 40;
BA_ "GenSigSendType" SG_ 871 EDS_MotorTemp 0;
VAL_ 133 Rolling_Counter_0x85 15 "Invalid" ;
VAL_ 133 ACU_Crash_Sts 3 "Invalid Value" 2 "Invalid Value" 1 "Crash_Detected" 0 "No_Event" ;
VAL_ 133 ACU_Airbag_Deployment_Status 3 "Invalid Value" 2 "Invalid Value" 1 "Airbag_Deployment" 0 "No_Airbag_Deployment" ;
VAL_ 897 Rolling_Counter_0x381 15 "Invalid" ;
VAL_ 897 ACU_Seat_Occupancy_Passenger 3 "Failure" 2 "Not_Available" 1 "Seat Occupied" 0 "Seat_Not_Occupied" ;
VAL_ 897 ACU_Seat_Belt_Status_Passenger 3 "Failure" 2 "Not_Available" 1 "Buckled" 0 "Not_buckled" ;
VAL_ 897 ACU_Seat_Belt_Status_Driver 3 "Failure" 2 "Not_Available" 1 "Buckled" 0 "Not_buckled" ;
VAL_ 1160 Alive_ACU_0x488 21 "Invalid" ;
VAL_ 1160 ACU_Malfunction 0 "ACU_Failure" 1 "ACU_Normal_Operation" ;
VAL_ 1160 ACU_Pre_Drive_Check 0 "ACU_Pre_Drive_Check" 1 "ACU_Normal_Operation" ;
VAL_ 1160 ACU_in_Plant_Mode 0 "ACU_in_Plant_Mode" 1 "ACU_in_Normal_Mode" ;
VAL_ 1160 ACU_PAB_Suppression 0 "Not_Suppressed" 1 "Suppressed" 2 "Function Failure" 3 "Invalid_Value" ;
VAL_ 1160 ACU_Airbag_Disabled 0 "ACU_AirBag_Disabled" 1 "ACU_Normal_Operation" ;
VAL_ 1160 ACU_Development_Calibration 0 "ACU_Dev_Calibrated" 1 "ACU_Normal_Operation" ;
VAL_ 1160 ACU_In_Disposal_Mode 0 "ACU_In_Disposal_Mode" 1 "ACU_Normal_Operation" ;
VAL_ 1160 ACU_VehicleFailureLevel 0 "Normal" 1 "Slight Fault" 2 "Minor fault" 3 "General fault" 4 "Serious Fault" 5 "Fatal fault" ;
VAL_ 1160 ACU_Seatbelt_Reminder_Request 0 "Seatbelt reminder NOT activated" 1 "Seatbelt reminder activated" ;
VAL_ 1160 ACU_SBR_Chime_Req 0 "No Active Chime" 1 "Active Chime" ;
VAL_ 1160 ACU_SBR_Blinking_Req 0 "No Blinking" 1 "Blinking 1Hz" ;
VAL_ 281 ABS_DTCDecReqTorque 4095 " Invalid" ;
VAL_ 281 ABS_DTCActiveSts 0 "Not Active" 1 " Active" ;
VAL_ 281 ABS_DTCSystemSts 0 "No Fault" 1 "Fault" ;
VAL_ 281 ABS_DTCDecReqTorqueV 0 "Invalid" 1 "Valid" ;
VAL_ 281 ABS_ASRDecReqTorque 4095 " Invalid" ;
VAL_ 281 ABS_ASRSwState 0 "OFF(关闭PTC功能)" 1 "ON(开启PTC功能)" ;
VAL_ 281 ABS_ASRActiveSts 0 "Not Active" 1 " Active" ;
VAL_ 281 ABS_ASRSystemSts 0 "Normal" 1 "Fault" ;
VAL_ 281 ABS_ASRDecReqTorqueV 0 "Invalid" 1 "Valid" ;
VAL_ 281 ABS_MasterCylinderPressure 4095 "Invalid" ;
VAL_ 280 ALIVE_ABS_0x118 15 "Invalid" ;
VAL_ 280 ABS_HazardLightsOnReq 0 "No request" 1 "request" ;
VAL_ 280 ABS_BrakeLightsOnReq 0 "No request" 1 "request" ;
VAL_ 280 ABS_TcsFlgFlt 1 "Failure" 0 "no Failure" ;
VAL_ 280 ABS_TCS_Active 1 "active" 0 "inactive" ;
VAL_ 280 ABS_ABSActive 1 "active" 0 "inactive" ;
VAL_ 280 ABS_EBDFault 1 "Fault" 0 "Normal" ;
VAL_ 280 ABS_ABSFault 1 "Fault" 0 "Normal" ;
VAL_ 280 ABS_TCS_OFF_State 1 "open" 0 "close" ;
VAL_ 280 ABS_VehicleFailureLevel 0 "Normal" 1 "Slight Fault" 2 "Minor fault" 3 "General fault" 4 "Serious Fault" 5 "Fatal fault" ;
VAL_ 280 ABS_RBSInhibitFlag 0 "Not Inhibit" 1 "Inhibit" ;
VAL_ 280 ABS_EBDActive 1 "active" 0 "inactive" ;
VAL_ 280 ABS_VehicleSpeed 32767 "Invalid" ;
VAL_ 280 ABS_VehicleSpeedV 0 "Invalid" 1 "Valid" ;
VAL_ 275 ABS_WheelSpeedFL 8191 "Invalid" ;
VAL_ 275 ABS_PulseCounterFLV 0 "Invalid" 1 "Valid" ;
VAL_ 275 ABS_WheelSpeedFLV 0 "Invalid" 1 "Valid" ;
VAL_ 275 ABS_WheelSpeedFR 8191 "Invalid" ;
VAL_ 275 ABS_PulseCounterFRV 0 "Invalid" 1 "Valid" ;
VAL_ 275 ABS_WheelSpeedFRV 0 "Invalid" 1 "Valid" ;
VAL_ 274 ABS_WheelSpeedRL 8191 "Invalid" ;
VAL_ 274 ABS_PulseCounterRLV 0 "Invalid" 1 "Valid" ;
VAL_ 274 ABS_WheelSpeedRLV 0 "Invalid" 1 "Valid" ;
VAL_ 274 ABS_WheelSpeedRR 8191 "Invalid" ;
VAL_ 274 ABS_PulseCounterRRV 0 "Invalid" 1 "Valid" ;
VAL_ 274 ABS_WheelSpeedRRV 0 "Invalid" 1 "Valid" ;
VAL_ 1145 VCU_VehicleFailureLevel 0 "Normal" 1 "Slight Fault" 2 "Minor fault" 3 "General fault" 4 "Serious Fault" 5 "Fatal fault" ;
VAL_ 1145 VCU_EDSCAN_ERR 1 "Error" 0 "Normal" ;
VAL_ 1145 VCU_BmsCAN_ERR 1 "Error" 0 "Normal" ;
VAL_ 1145 VCU_DcdcCAN_ERR 1 "Error" 0 "Normal" ;
VAL_ 1145 VCU_AbsCAN_ERR 1 "Error" 0 "Normal" ;
VAL_ 1145 VCU_ACUCAN_ERR 1 "Error" 0 "Normal" ;
VAL_ 1145 VCU_BcmCAN_ERR_reserved 1 "Error" 0 "Normal" ;
VAL_ 1145 VCU_BrakeSys_Err 1 "Error" 0 "Normal" ;
VAL_ 1145 VCU_AccPed_ERR 1 "Error" 0 "Normal" ;
VAL_ 1145 VCU_Shift_ERR 1 "Error" 0 "Normal" ;
VAL_ 1145 VCU_EPSCAN_ERR 1 "Error" 0 "Normal" ;
VAL_ 1145 VCU_EvccCAN_ERR 1 "Error" 0 "Normal" ;
VAL_ 1145 VCU_FlgHVIL_ERR 1 "Error" 0 "Normal" ;
VAL_ 1145 VCU_ObcCAN_ERR 1 "Error" 0 "Normal" ;
VAL_ 1145 VCU_SSCAN_ERR 1 "Error" 0 "Normal" ;
VAL_ 1145 VCU_EacCAN_ERR 1 "Error" 0 "Normal" ;
VAL_ 1145 VCU_AccPedalOutRange 1 "Error" 0 "Normal" ;
VAL_ 1221 VCU_CreepDisable_stt 0 "Enable" 1 "disable" ;
VAL_ 1221 VCU_RDCSts 0 "inactive" 1 "Active" ;
VAL_ 1221 VCU_RBCSts 0 "inactive" 1 "Active" ;
VAL_ 1221 VCU_BrkPedalSWSts 0 "Notpressed" 1 "pressed" 2 "notused" 3 "Invalid" ;
VAL_ 1221 Brakefluid_levelSts 0 "Normal" 1 "Low" 2 "Disconnect" 3 "reserve" ;
VAL_ 1221 VCU_HandBrakeSts 0 "released" 1 "notreleased" ;
VAL_ 1221 VCU_RegenLevelfeed 0 "OFF" 1 "ON" ;
VAL_ 1221 VCU_PowerLimit 0 "NoLimit" 1 "Limit" ;
VAL_ 1221 VCU_AccPedaPosValid 0 "Valid" 1 "Invalid" ;
VAL_ 1221 VCU_VehicleHVStatus 0 "NotReady" 1 "HVOn" 2 "Ready" ;
VAL_ 1221 VCU_VacuumPresWrn 0 "Normal" 1 "Slight Insufficient" 2 "Serious Insufficient" 3 "Invalid" ;
VAL_ 1221 VCU_VacuumSts 0 "Normal" 1 "slow leak" 2 "quick leak" 3 "Invalid" ;
VAL_ 1221 VCU_InstantPowerConsump 1023 "Invalid" ;
VAL_ 1221 VCU_AveragePowerConsump 1023 "Invalid" ;
VAL_ 1221 VCU_LowSOCWarning 0 "Normal" 1 "Low SOC" ;
VAL_ 1221 VCU_TqReductionRqstResponse 0 "inactive" 1 "Active" ;
VAL_ 1221 VCU_DrvModeSts 0 "Normal(正常模式)" 1 "Eco(经济模式)" 2 "Sport(运动模式)" 3 "Reserved(预留)" ;
VAL_ 905 VCU_VacuumPumpEna 1 "Enable" 0 "Disable" ;
VAL_ 341 ALIVE_VCU_0x155 15 "Invalid" ;
VAL_ 341 VCU_VecChrgRqst 0 "Default" 1 "permit" 2 "forbid" ;
VAL_ 341 VCU_Vechg_Status 3 "Charging Fault" 2 "Charging Complete" 1 "Charging in process" 0 "Charging not in process" ;
VAL_ 341 VCU_VecOptMod 0 "Sleep(休眠)" 1 "Initial(初始化)" 2 "PowerOn(上电)" 3 "Drive(行驶)" 4 "Charging(充电)" 5 "PowerOFF(下电)" 6 "Err(故障)" 7 "LimpHome" 8 "LVCharging(馈电补电)" ;
VAL_ 341 VCU_BMSHvPowOnRqst 1 "allow" 0 "forbid" ;
VAL_ 341 VCU_VecActGearStsV 1 "Invalid" 0 "Valid" ;
VAL_ 341 VCU_VecActGearSts 7 "Fault" 6 "Reserved" 5 "Reserved" 4 "Reserved" 3 "D" 2 "N" 1 "R" 0 "P" ;
VAL_ 341 VCU_LV_topupSts 3 "Rserved" 2 "Finish supply" 1 "suppling" 0 "dissupply" ;
VAL_ 341 VCU_DrTorqRqstV 1 "Invalid" 0 "Valid" ;
VAL_ 341 VCU_ABS_TrqReqOrLmt 65535 "Invalid" ;
VAL_ 288 VCU_RemainMileageVD 0 "Valid" 1 "Invalid" ;
VAL_ 291 ALIVE_VCU_0x123 15 "Invalid" ;
VAL_ 291 VCU_Drive_TargetTqMin 1023 "Invalid" ;
VAL_ 291 VCU_Drive_TargetTqMax 1023 "Invalid" ;
VAL_ 525 Rolling_Counter_0x20D 15 "Invalid" ;
VAL_ 525 VCU_ODO 1048575 "Invalid" ;
VAL_ 1074 Rolling_Counter_0x432 15 "Invalid" ;
VAL_ 1074 IPC_FOTA_State 0 "INIT" 1 "NORMAL" 2 "FOTA FLASHING" 3 "Reserved" 4 "FAIL-SAFE-ERROR" 5 "Reserved" 6 "REMOTE DIAGNOSTICS" 7 "Invalid" ;
VAL_ 1020 VCU_FOTA_StateConfirm 0 "INIT" 1 "NORMAL" 2 "FOTA FLASHING" 3 "Reserved" 4 "FAIL-SAFE-ERROR" 5 "Reserved" 6 "REMOTE DIAGNOSTICS" 7 "Invalid" ;
VAL_ 967 IPC_Wiper_Repair_Mode 0 "Off" 1 "On" 2 "no action" 3 "Invalid" ;
VAL_ 967 IPC_St_Dimming 15 "Invalid" 14 "Level 15" 13 "Level 14" 12 "Level 13" 11 "Level 12" 10 "Level 11" 9 "Level 10" 8 "Level 9" 7 "Level 8" 6 "Level 7" 5 "Level 6" 4 "Level 5" 3 "Level 4" 2 "Level 3" 1 "Level 2" 0 "Level 1" ;
VAL_ 703 IPC_TripA 65535 "Invalid" ;
VAL_ 703 IPC_AverageConsumptionTripA 1023 "Invalid" ;
VAL_ 703 IPC_AverageSpeedTripA 4095 "Invalid" ;
VAL_ 703 IPC_VehicleFailureLevel 0 "Normal" 1 "Slight Fault" 2 "Minor fault" 3 "General fault" 4 "Serious Fault" 5 "Fatal fault" ;
VAL_ 703 IPC_VehSpd 32767 "Invalid" ;
VAL_ 1087 IPC_Year 255 "Invalid" ;
VAL_ 1087 IPC_Month 15 "Invalid" ;
VAL_ 1087 IPC_SelFCheckStatus 1 "selF-check Finish" 0 "selF-checking" ;
VAL_ 1087 IPC_Day 31 "Invalid" ;
VAL_ 1087 IPC_Hour 31 "Invalid" ;
VAL_ 1087 IPC_Min 63 "Invalid" ;
VAL_ 1087 IPC_Sec 63 "Invalid" ;
VAL_ 524 IPC_ODO 1048575 "Invalid" ;
VAL_ 677 IPC_ChargeScheduleSet 0 "Disable" 1 "Enabled" 2 "No Action" 3 "Reserved" ;
VAL_ 677 IPC_ChargingRequest 0 "No Effect" 1 "Request scheduled start charging" 2 "Request stop" 3 "Reserved" ;
VAL_ 676 IPC_EnergyRecSet 0 "OFF(关闭)" 1 "ON(开启)" 2 "Reserved(预留)" 3 "Reserved(预留)" ;
VAL_ 676 IPC_HSA_Set 0 "OFF" 1 "ON" 2 "Reserved" 3 "Invalid" ;
VAL_ 676 IPC_DriveModeSet 0 "NoReq" 1 "NormalMode" 2 "ECOmode" 3 "SportMode(预留)" ;
VAL_ 676 IPC_VCU_CreepDisable_Stt 0 "No request" 1 "request" ;
VAL_ 676 IPC_DriveLockSpeedCtl 0 "OFF" 1 "5KMH" 2 "10KMH" 3 "15KMH" 4 "20KMH" 5 "25KMH" 6 "Signal invalid" ;
VAL_ 1015 MFS_RightControl 0 "Button not Pressed" 1 "Short Press" 2 "Long Press" 3 "Signal invalid" ;
VAL_ 1015 MFS_LeftControl 0 "Button not Pressed" 1 "Short Press" 2 "Long Press" 3 "Signal invalid" ;
VAL_ 1015 MFS_DownControl 0 "Button not Pressed" 1 "Short Press" 2 "Long Press" 3 "Signal invalid" ;
VAL_ 1015 MFS_UpControl 0 "Button not Pressed" 1 "Short Press" 2 "Long Press" 3 "Signal invalid" ;
VAL_ 1015 MFS_Failure 0 "No Error" 1 "Error" ;
VAL_ 1015 MFS_VOL_D 3 "Signal invalid" 2 "Long Press" 1 "Short Press" 0 "Unpress" ;
VAL_ 1015 MFS_VOL_U 3 "Signal invalid" 2 "Long Press" 1 "Short Press" 0 "Unpress" ;
VAL_ 1015 MFS_OK_Control 0 "Button not Pressed" 1 "Short Press" 2 "Long Press" 3 "Signal invalid" ;
VAL_ 264 Rolling_Counter_0x108 15 "Invalid" ;
VAL_ 264 SS_DriveModeReq_reserved 1 "press" 0 "no press" ;
VAL_ 264 SS_TargetGearReq 7 "Reserved" 4 "Invalid" 3 "D" 2 "N" 1 "R" 0 "Stop Charging" ;
VAL_ 264 SS_Fault 6 "Received Date from BCM is invalid" 5 "Received Date from VCU is invalid" 4 "Supply voltage failure" 3 "Position sensor failure" 2 "CAN communication fail" 1 "Shifter failure" 0 "normal" ;
VAL_ 264 FR_Wipercontrol_switch 7 "Invalid " 6 "reserved " 5 "reserved " 4 "High " 3 "Int2 " 2 "Int1 " 1 "Low " 0 "OFF" ;
VAL_ 264 Front_Wash 3 "Invalid " 2 "Wash " 1 "Mist" 0 "OFF" ;
VAL_ 264 SS_FogLight_reserved 0 "OFF" 1 "ON" ;
VAL_ 264 RR_Wiper 3 "Invalid " 2 "Wash " 1 "Wipe " 0 "OFF" ;
VAL_ 264 SS_lane_change_lampSts 0 "OFF" 1 "Left lane change" 2 "Right lane change" 3 "Reserved" ;
VAL_ 264 SS_Overtaking_lamp 0 "OFF" 1 "ON" ;
VAL_ 264 SS_TurnIndicatorSts 0 "OFF" 1 "Left On" 2 "Right On" 3 "Reserved" ;
VAL_ 264 SS_PosLmpSts 0 "OFF " 1 "ON" ;
VAL_ 264 SS_LowBeamSts 0 "OFF" 1 "ON" ;
VAL_ 264 SS_HighBeamSts 0 "OFF" 1 "ON" ;
VAL_ 1236 BCM_FrontLeftDoorAjarStatus 0 "Closed" 1 "Opened" 2 "Reserved" 3 "Signal invalid" ;
VAL_ 1236 BCM_FrontRightDoorAjarStatus 0 "Closed" 1 "Opened" 2 "Reserved" 3 "Signal invalid" ;
VAL_ 1236 BCM_RightDoorLockStatusDrv 0 "Unlcoked" 1 "Locked" 2 "Reserved" 3 "Signal invalid" ;
VAL_ 1236 BCM_LeftDoorLockStatusDrv 0 "Unlcoked" 1 "Locked" 2 "Reserved" 3 "Signal invalid" ;
VAL_ 1236 BCM_ATWS_St 0 "Secured" 1 "Unsecured" 2 "Alarm" 3 "Partly secured" 4 "Security Failure" 5 "Reserved" 6 "Reserved" 7 "Signal invalid" ;
VAL_ 1236 BCM_STAT_DoorSpeedLock 0 "OFF" 1 "5KMH" 2 "10KMH" 3 "15KMH" 4 "20KMH" 5 "25KMH" 6 "Signal invalid" ;
VAL_ 262 BCM_TurnIndicatorSts 0 "OFF" 1 "LeftOn" 2 "RightOn" 3 "Hazard warning light" ;
VAL_ 262 BCM_PosLmpSts 0 "OFF" 1 "ON" 2 "Fault(Reserved)" 3 "SignalInvalid" ;
VAL_ 262 BCM_LowBeamSts 0 "OFF" 1 "ON" 2 "Fault(Reserved)" 3 "SignalInvalid" ;
VAL_ 262 BCM_HighBeamSts 0 "OFF" 1 "ON" 2 "Fault(Reserved)" 3 "SignalInvalid" ;
VAL_ 262 BCM_BrakeLightSts 0 "OFF" 1 "ON" 2 "Fault(Reserved)" 3 "SignalInvalid" ;
VAL_ 262 BCM_ReverseLightSts 0 "OFF" 1 "ON" 2 "Fault(Reserved)" 3 "SignalInvalid" ;
VAL_ 262 BCM_STAT_LightActivation 0 "OFF" 1 "PositionLight" 2 "LowBeam" 3 "AutoLight" 4 "Reserved" 5 "Reserved" 6 "Reserved" 7 "Signalinvalid" ;
VAL_ 262 BCM_Fr_domelampSts 0 "OFF" 1 "ON" 2 "Fault(Reserved)" 3 "SignalInvalid" ;
VAL_ 262 BCM_LicensePlateLightSts 0 "OFF" 1 "ON" 2 "Fault(Reserved)" 3 "SignalInvalid" ;
VAL_ 262 BCM_STAT_InteriorLight 0 "OFF" 1 "ON" 2 "Fault(Reserved)" 3 "SignalInvalid" ;
VAL_ 513 BCM_LV_topupReq 0 "inactive" 1 "Active" 2 "Rserved" 3 "Rserved" ;
VAL_ 513 BCM_BatteryVoltage 597 "Invalid" ;
VAL_ 513 BCM_Key_CheckSts 0 "Passed" 1 "Invalid" ;
VAL_ 513 BCM_Press_BrkPedal_Alert 0 "inactive" 1 "Active" ;
VAL_ 513 BCM_EmergencyStop 0 "Normal" 1 "EmergencyStop" 2 "Rserved" 3 "Invalid" ;
VAL_ 513 BCM_IGN1RelayOutputSts 0 "inactive" 1 "Active" 2 "Reserved" 3 "Reserved" ;
VAL_ 513 BCM_ACCRelayOutputSts 0 "inactive" 1 "Active" 2 "Reserved" 3 "Reserved" ;
VAL_ 513 BCM_FLWIN_Postion_Reserved 0 "NotActive" 1 "Closed(Top)" 2 "Open(Bottom)" 3 "80%-Close(Reserved)" 4 "Open-80%(Reserved)" 5 "opening" 6 "closing" 7 "Reserved" ;
VAL_ 513 BCM_KEY_MatchSts 0 "No Match" 1 "Match Success" 2 "Match Failed" 3 "Matching" ;
VAL_ 513 BCM_FRWIN_Postion_Reserved 0 "NotActive" 1 "Closed(Top)" 2 "Open(Bottom)" 3 "80%-Close(Reserved)" 4 "Open-80%(Reserved)" 5 "opening" 6 "closing" 7 "Reserved" ;
VAL_ 513 BCM_PowerMode 0 "OFF" 1 "ACC" 2 "ON" 3 "START" ;
VAL_ 513 BCM_BrakeSwSts 0 "Notpressed" 1 "pressed" 2 "notused" 3 "Invalid" ;
VAL_ 513 BCM_VehicleFailureLevel 0 "Normal" 1 "Slight Fault" 2 "Minor fault" 3 "General fault" 4 "Serious Fault" 5 "Fatal fault" ;
VAL_ 513 BCM_Anti_theftAlarmSetSts 0 "Light" 1 "Horn" 2 "Both" 3 "Invalid" ;
VAL_ 513 BCM_FMH_SetSts 0 "OFF" 1 "30s" 2 "60s" 3 "90s" ;
VAL_ 513 BCM_IGN1RelayFaultSts 0 "No Fault" 1 "Fault" 2 "Reserved" 3 "Signal Invalid" ;
VAL_ 513 BCM_ACCRelayFaultSts 0 "No Fault" 1 "Fault" 2 "Reserved" 3 "Signal Invalid" ;
VAL_ 201 EDS_VCU_CtrMode 0 "Inactive" 1 "Toque control mode" 2 "Anti-slide slope" 3 "reserved" ;
VAL_ 201 EDS_MotorSpdVD 0 "Valid" 1 "Invalid" ;
VAL_ 201 EDS_MotorTqVD 0 "Valid" 1 "Invalid" ;
VAL_ 201 EDS_MotorTq 65534 "Abnormal" 65535 "Invaild" ;
VAL_ 201 EDS_MotorSpd 65534 "Abnormal" 65535 "Invaild" ;
VAL_ 201 EDS_HSA_Sts 0 "Inactive" 1 "Active" 2 "Reserved" 3 "Invalid" ;
VAL_ 201 EDS_DriveSTS 0 "Regeneration control" 1 "Drive control" 2 "Zero control" ;
VAL_ 201 EDS_StsMode 0 "DeFault(默认值)" 1 "Init(初始化)" 2 "Standby(待机)" 3 "Precharge(预充)" 4 "Normal(正常运行)" 5 "HVReady(高压上电完成)" 11 "ShutDown(关闭)" 12 "AFterRun(运行后)" 13 "Failure" 14 "PowerOFF(下电)" ;
VAL_ 201 EDS_VehicleFailureLevel 0 "Normal" 1 "Slight Fault" 2 "Minor fault" 3 "General fault" 4 "Serious Fault" 5 "Fatal fault" ;
VAL_ 201 EDS_HSA_Fault 0 "Normal" 1 "Level 1" 2 "Level 2" 3 "Invalid" ;
VAL_ 871 ALIVE_EDS_0x367 15 "Invalid" ;
